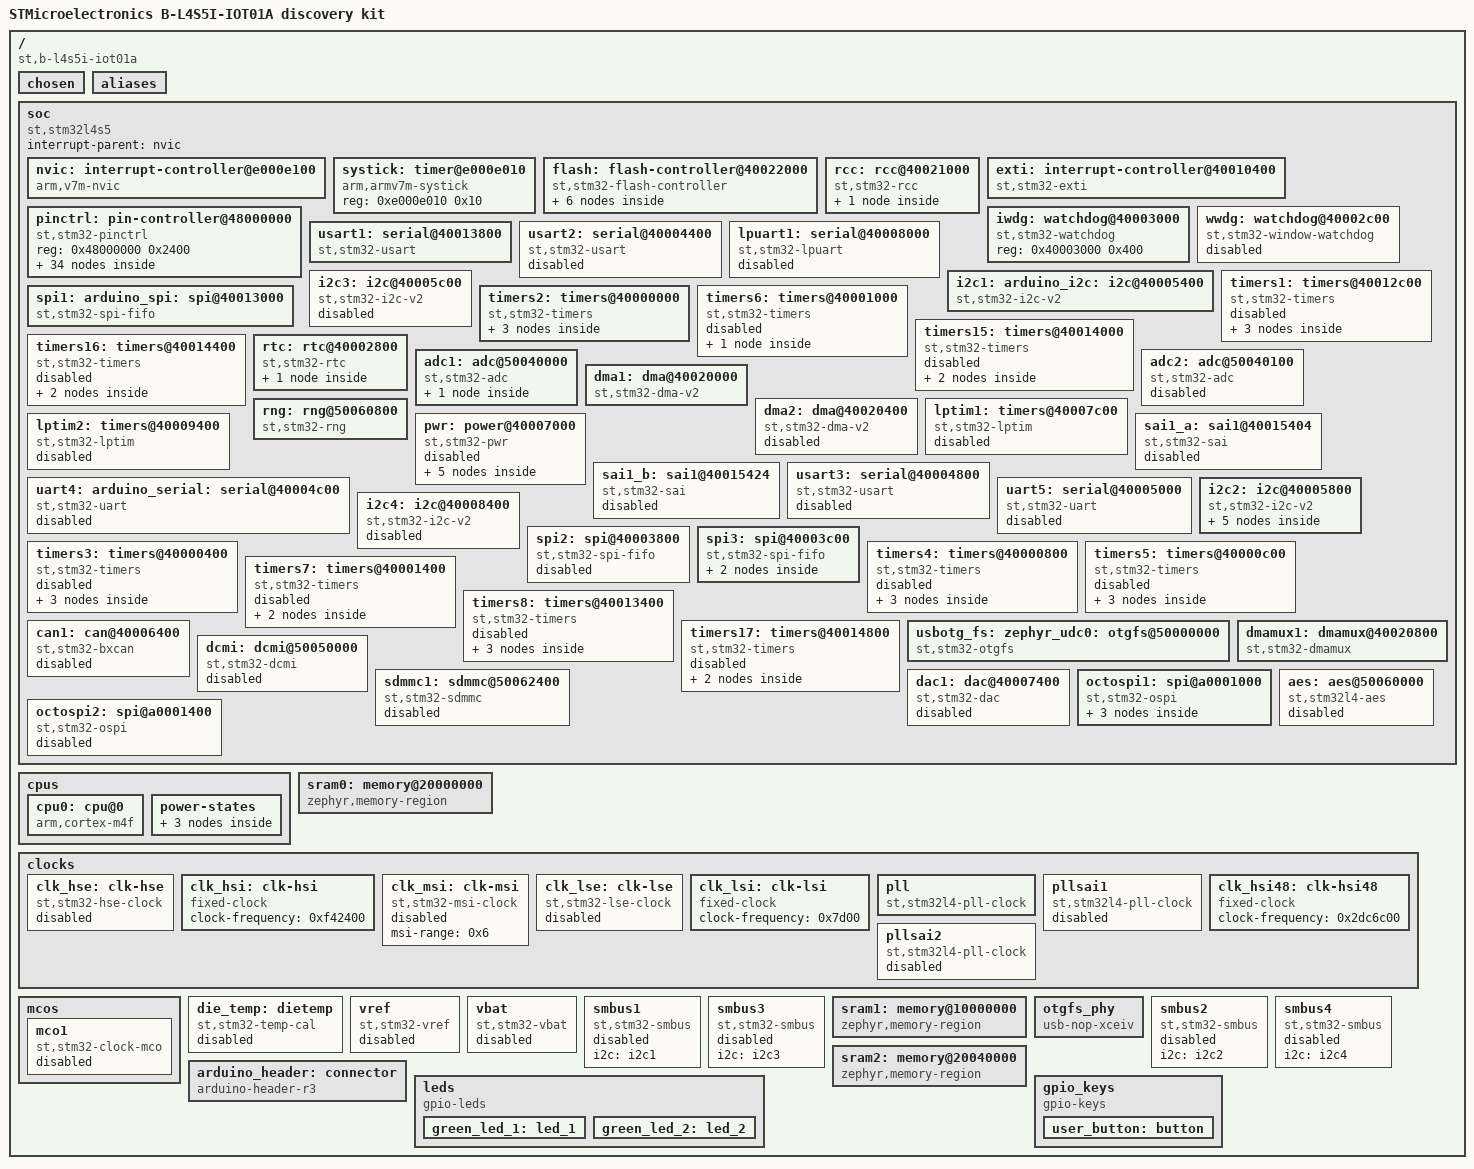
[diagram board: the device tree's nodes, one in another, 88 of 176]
/dts-v1/;

/* node '/' defined in zephyr\dts\common\skeleton.dtsi:9 */
/ {
	#address-cells = < 0x1 >;                                  /* in zephyr\dts\common\skeleton.dtsi:10 */
	#size-cells = < 0x1 >;                                     /* in zephyr\dts\common\skeleton.dtsi:11 */
	model = "STMicroelectronics B-L4S5I-IOT01A discovery kit"; /* in zephyr\boards\st\b_l4s5i_iot01a\b_l4s5i_iot01a.dts:14 */
	compatible = "st,b-l4s5i-iot01a";                          /* in zephyr\boards\st\b_l4s5i_iot01a\b_l4s5i_iot01a.dts:15 */

	/* node '/chosen' defined in zephyr\dts\common\skeleton.dtsi:13 */
	chosen {
		zephyr,entropy = &rng;                    /* in zephyr\dts\arm\st\l4\stm32l4.dtsi:25 */
		zephyr,console = &usart1;                 /* in zephyr\boards\st\b_l4s5i_iot01a\b_l4s5i_iot01a.dts:18 */
		zephyr,shell-uart = &usart1;              /* in zephyr\boards\st\b_l4s5i_iot01a\b_l4s5i_iot01a.dts:19 */
		zephyr,sram = &sram0;                     /* in zephyr\boards\st\b_l4s5i_iot01a\b_l4s5i_iot01a.dts:20 */
		zephyr,flash = &flash0;                   /* in zephyr\boards\st\b_l4s5i_iot01a\b_l4s5i_iot01a.dts:21 */
		zephyr,code-partition = &slot0_partition; /* in zephyr\boards\st\b_l4s5i_iot01a\b_l4s5i_iot01a.dts:22 */
		zephyr,flash-controller = &mx25r6435f;    /* in zephyr\boards\st\b_l4s5i_iot01a\b_l4s5i_iot01a.dts:23 */
		zephyr,bt-c2h-uart = &usart1;             /* in zephyr\boards\st\b_l4s5i_iot01a\b_l4s5i_iot01a.dts:24 */
		zephyr,bt-hci = &hci_spi;                 /* in zephyr\boards\st\b_l4s5i_iot01a\b_l4s5i_iot01a.dts:25 */
	};

	/* node '/aliases' defined in zephyr\dts\common\skeleton.dtsi:15 */
	aliases {
		led0 = &green_led_1; /* in zephyr\boards\st\b_l4s5i_iot01a\b_l4s5i_iot01a.dts:53 */
		sw0 = &user_button;  /* in zephyr\boards\st\b_l4s5i_iot01a\b_l4s5i_iot01a.dts:54 */
		watchdog0 = &iwdg;   /* in zephyr\boards\st\b_l4s5i_iot01a\b_l4s5i_iot01a.dts:55 */
		accel0 = &lsm6dsl;   /* in zephyr\boards\st\b_l4s5i_iot01a\b_l4s5i_iot01a.dts:56 */
	};

	/* node '/soc' defined in zephyr\dts\arm\armv7-m.dtsi:6 */
	soc {
		#address-cells = < 0x1 >;     /* in zephyr\dts\arm\armv7-m.dtsi:7 */
		#size-cells = < 0x1 >;        /* in zephyr\dts\arm\armv7-m.dtsi:8 */
		interrupt-parent = < &nvic >; /* in zephyr\dts\arm\armv7-m.dtsi:10 */
		ranges;                       /* in zephyr\dts\arm\armv7-m.dtsi:11 */
		compatible = "st,stm32l4s5",
		             "st,stm32l4",
		             "simple-bus";    /* in zephyr\dts\arm\st\l4\stm32l4s5.dtsi:11 */

		/* node '/soc/interrupt-controller@e000e100' defined in zephyr\dts\arm\armv7-m.dtsi:13 */
		nvic: interrupt-controller@e000e100 {
			#address-cells = < 0x1 >;            /* in zephyr\dts\arm\armv7-m.dtsi:14 */
			compatible = "arm,v7m-nvic";         /* in zephyr\dts\arm\armv7-m.dtsi:15 */
			reg = < 0xe000e100 0xc00 >;          /* in zephyr\dts\arm\armv7-m.dtsi:16 */
			interrupt-controller;                /* in zephyr\dts\arm\armv7-m.dtsi:17 */
			#interrupt-cells = < 0x2 >;          /* in zephyr\dts\arm\armv7-m.dtsi:18 */
			arm,num-irq-priority-bits = < 0x4 >; /* in zephyr\dts\arm\st\l4\stm32l4.dtsi:597 */
			phandle = < 0x1 >;                   /* in zephyr\dts\arm\armv7-m.dtsi:10 */
		};

		/* node '/soc/timer@e000e010' defined in zephyr\dts\arm\armv7-m.dtsi:21 */
		systick: timer@e000e010 {
			compatible = "arm,armv7m-systick"; /* in zephyr\dts\arm\armv7-m.dtsi:22 */
			reg = < 0xe000e010 0x10 >;         /* in zephyr\dts\arm\armv7-m.dtsi:23 */
		};

		/* node '/soc/flash-controller@40022000' defined in zephyr\dts\arm\st\l4\stm32l4.dtsi:126 */
		flash: flash-controller@40022000 {
			compatible = "st,stm32-flash-controller",
			             "st,stm32l4-flash-controller"; /* in zephyr\dts\arm\st\l4\stm32l4.dtsi:127 */
			reg = < 0x40022000 0x400 >;                 /* in zephyr\dts\arm\st\l4\stm32l4.dtsi:128 */
			interrupts = < 0x4 0x0 >;                   /* in zephyr\dts\arm\st\l4\stm32l4.dtsi:129 */
			clocks = < &rcc 0x48 0x100 >;               /* in zephyr\dts\arm\st\l4\stm32l4.dtsi:130 */
			#address-cells = < 0x1 >;                   /* in zephyr\dts\arm\st\l4\stm32l4.dtsi:132 */
			#size-cells = < 0x1 >;                      /* in zephyr\dts\arm\st\l4\stm32l4.dtsi:133 */

			/* node '/soc/flash-controller@40022000/flash@8000000' defined in zephyr\dts\arm\st\l4\stm32l4.dtsi:135 */
			flash0: flash@8000000 {
				compatible = "st,stm32-nv-flash",
				             "soc-nv-flash";      /* in zephyr\dts\arm\st\l4\stm32l4.dtsi:136 */
				write-block-size = < 0x8 >;       /* in zephyr\dts\arm\st\l4\stm32l4.dtsi:138 */
				max-erase-time = < 0x19 >;        /* in zephyr\dts\arm\st\l4\stm32l4.dtsi:141 */
				erase-block-size = < 0x1000 >;    /* in zephyr\dts\arm\st\l4\stm32l4p5.dtsi:53 */
				reg = < 0x8000000 0x200000 >;     /* in zephyr\dts\arm\st\l4\stm32l4s5Xi.dtsi:13 */

				/* node '/soc/flash-controller@40022000/flash@8000000/partitions' defined in zephyr\boards\st\b_l4s5i_iot01a\b_l4s5i_iot01a.dts:179 */
				partitions {
					compatible = "fixed-partitions"; /* in zephyr\boards\st\b_l4s5i_iot01a\b_l4s5i_iot01a.dts:180 */
					#address-cells = < 0x1 >;        /* in zephyr\boards\st\b_l4s5i_iot01a\b_l4s5i_iot01a.dts:181 */
					#size-cells = < 0x1 >;           /* in zephyr\boards\st\b_l4s5i_iot01a\b_l4s5i_iot01a.dts:182 */

					/* node '/soc/flash-controller@40022000/flash@8000000/partitions/partition@0' defined in zephyr\boards\st\b_l4s5i_iot01a\b_l4s5i_iot01a.dts:184 */
					boot_partition: partition@0 {
						label = "mcuboot";     /* in zephyr\boards\st\b_l4s5i_iot01a\b_l4s5i_iot01a.dts:185 */
						reg = < 0x0 0x10000 >; /* in zephyr\boards\st\b_l4s5i_iot01a\b_l4s5i_iot01a.dts:186 */
						read-only;             /* in zephyr\boards\st\b_l4s5i_iot01a\b_l4s5i_iot01a.dts:187 */
					};

					/* node '/soc/flash-controller@40022000/flash@8000000/partitions/partition@10000' defined in zephyr\boards\st\b_l4s5i_iot01a\b_l4s5i_iot01a.dts:190 */
					slot0_partition: partition@10000 {
						label = "image-0";         /* in zephyr\boards\st\b_l4s5i_iot01a\b_l4s5i_iot01a.dts:191 */
						reg = < 0x10000 0xf4000 >; /* in zephyr\boards\st\b_l4s5i_iot01a\b_l4s5i_iot01a.dts:192 */
					};

					/* node '/soc/flash-controller@40022000/flash@8000000/partitions/partition@104000' defined in zephyr\boards\st\b_l4s5i_iot01a\b_l4s5i_iot01a.dts:195 */
					slot1_partition: partition@104000 {
						label = "image-1";          /* in zephyr\boards\st\b_l4s5i_iot01a\b_l4s5i_iot01a.dts:196 */
						reg = < 0x104000 0xf4000 >; /* in zephyr\boards\st\b_l4s5i_iot01a\b_l4s5i_iot01a.dts:197 */
					};

					/* node '/soc/flash-controller@40022000/flash@8000000/partitions/partition@1f8000' defined in zephyr\boards\st\b_l4s5i_iot01a\b_l4s5i_iot01a.dts:200 */
					storage_partition: partition@1f8000 {
						label = "storage";         /* in zephyr\boards\st\b_l4s5i_iot01a\b_l4s5i_iot01a.dts:201 */
						reg = < 0x1f8000 0x8000 >; /* in zephyr\boards\st\b_l4s5i_iot01a\b_l4s5i_iot01a.dts:202 */
					};
				};
			};
		};

		/* node '/soc/rcc@40021000' defined in zephyr\dts\arm\st\l4\stm32l4.dtsi:145 */
		rcc: rcc@40021000 {
			compatible = "st,stm32-rcc";     /* in zephyr\dts\arm\st\l4\stm32l4.dtsi:146 */
			#clock-cells = < 0x2 >;          /* in zephyr\dts\arm\st\l4\stm32l4.dtsi:147 */
			reg = < 0x40021000 0x400 >;      /* in zephyr\dts\arm\st\l4\stm32l4.dtsi:148 */
			undershoot-prevention;           /* in zephyr\dts\arm\st\l4\stm32l4p5.dtsi:58 */
			clocks = < &pll >;               /* in zephyr\boards\st\b_l4s5i_iot01a\b_l4s5i_iot01a.dts:82 */
			clock-frequency = < 0x4c4b400 >; /* in zephyr\boards\st\b_l4s5i_iot01a\b_l4s5i_iot01a.dts:83 */
			ahb-prescaler = < 0x1 >;         /* in zephyr\boards\st\b_l4s5i_iot01a\b_l4s5i_iot01a.dts:84 */
			apb1-prescaler = < 0x1 >;        /* in zephyr\boards\st\b_l4s5i_iot01a\b_l4s5i_iot01a.dts:85 */
			apb2-prescaler = < 0x1 >;        /* in zephyr\boards\st\b_l4s5i_iot01a\b_l4s5i_iot01a.dts:86 */
			phandle = < 0x2 >;               /* in zephyr\dts\arm\st\l4\stm32l4.dtsi:130 */

			/* node '/soc/rcc@40021000/reset-controller' defined in zephyr\dts\arm\st\l4\stm32l4.dtsi:150 */
			rctl: reset-controller {
				compatible = "st,stm32-rcc-rctl"; /* in zephyr\dts\arm\st\l4\stm32l4.dtsi:151 */
				#reset-cells = < 0x1 >;           /* in zephyr\dts\arm\st\l4\stm32l4.dtsi:152 */
				phandle = < 0x4 >;                /* in zephyr\dts\arm\st\l4\stm32l4.dtsi:229 */
			};
		};

		/* node '/soc/interrupt-controller@40010400' defined in zephyr\dts\arm\st\l4\stm32l4.dtsi:156 */
		exti: interrupt-controller@40010400 {
			compatible = "st,stm32-exti";  /* in zephyr\dts\arm\st\l4\stm32l4.dtsi:157 */
			interrupt-controller;          /* in zephyr\dts\arm\st\l4\stm32l4.dtsi:158 */
			#interrupt-cells = < 0x1 >;    /* in zephyr\dts\arm\st\l4\stm32l4.dtsi:159 */
			#address-cells = < 0x0 >;      /* in zephyr\dts\arm\st\l4\stm32l4.dtsi:160 */
			reg = < 0x40010400 0x400 >;    /* in zephyr\dts\arm\st\l4\stm32l4.dtsi:161 */
			clocks = < &rcc 0x60 0x1 >;    /* in zephyr\dts\arm\st\l4\stm32l4.dtsi:162 */
			num-lines = < 0x40 >;          /* in zephyr\dts\arm\st\l4\stm32l4.dtsi:163 */
			interrupts = < 0x6 0x0 >,
			             < 0x7 0x0 >,
			             < 0x8 0x0 >,
			             < 0x9 0x0 >,
			             < 0xa 0x0 >,
			             < 0x17 0x0 >,
			             < 0x28 0x0 >;     /* in zephyr\dts\arm\st\l4\stm32l4.dtsi:164 */
			interrupt-names = "line0",
			                  "line1",
			                  "line2",
			                  "line3",
			                  "line4",
			                  "line5-9",
			                  "line10-15"; /* in zephyr\dts\arm\st\l4\stm32l4.dtsi:166 */
			line-ranges = < 0x0 0x1 >,
			              < 0x1 0x1 >,
			              < 0x2 0x1 >,
			              < 0x3 0x1 >,
			              < 0x4 0x1 >,
			              < 0x5 0x5 >,
			              < 0xa 0x6 >;     /* in zephyr\dts\arm\st\l4\stm32l4.dtsi:168 */
		};

		/* node '/soc/pin-controller@48000000' defined in zephyr\dts\arm\st\l4\stm32l4.dtsi:172 */
		pinctrl: pin-controller@48000000 {
			compatible = "st,stm32-pinctrl"; /* in zephyr\dts\arm\st\l4\stm32l4.dtsi:173 */
			#address-cells = < 0x1 >;        /* in zephyr\dts\arm\st\l4\stm32l4.dtsi:174 */
			#size-cells = < 0x1 >;           /* in zephyr\dts\arm\st\l4\stm32l4.dtsi:175 */
			reg = < 0x48000000 0x2400 >;     /* in zephyr\dts\arm\st\l4\stm32l4p5.dtsi:67 */

			/* node '/soc/pin-controller@48000000/gpio@48000000' defined in zephyr\dts\arm\st\l4\stm32l4.dtsi:178 */
			gpioa: gpio@48000000 {
				compatible = "st,stm32-gpio"; /* in zephyr\dts\arm\st\l4\stm32l4.dtsi:179 */
				gpio-controller;              /* in zephyr\dts\arm\st\l4\stm32l4.dtsi:180 */
				#gpio-cells = < 0x2 >;        /* in zephyr\dts\arm\st\l4\stm32l4.dtsi:181 */
				reg = < 0x48000000 0x400 >;   /* in zephyr\dts\arm\st\l4\stm32l4.dtsi:182 */
				clocks = < &rcc 0x4c 0x1 >;   /* in zephyr\dts\arm\st\l4\stm32l4.dtsi:183 */
				phandle = < 0xc >;            /* in zephyr\boards\st\b_l4s5i_iot01a\b_l4s5i_iot01a.dts:146 */
			};

			/* node '/soc/pin-controller@48000000/gpio@48000400' defined in zephyr\dts\arm\st\l4\stm32l4.dtsi:186 */
			gpiob: gpio@48000400 {
				compatible = "st,stm32-gpio"; /* in zephyr\dts\arm\st\l4\stm32l4.dtsi:187 */
				gpio-controller;              /* in zephyr\dts\arm\st\l4\stm32l4.dtsi:188 */
				#gpio-cells = < 0x2 >;        /* in zephyr\dts\arm\st\l4\stm32l4.dtsi:189 */
				reg = < 0x48000400 0x400 >;   /* in zephyr\dts\arm\st\l4\stm32l4.dtsi:190 */
				clocks = < &rcc 0x4c 0x2 >;   /* in zephyr\dts\arm\st\l4\stm32l4.dtsi:191 */
				phandle = < 0x1a >;           /* in zephyr\boards\st\b_l4s5i_iot01a\b_l4s5i_iot01a.dts:172 */
			};

			/* node '/soc/pin-controller@48000000/gpio@48000800' defined in zephyr\dts\arm\st\l4\stm32l4.dtsi:194 */
			gpioc: gpio@48000800 {
				compatible = "st,stm32-gpio"; /* in zephyr\dts\arm\st\l4\stm32l4.dtsi:195 */
				gpio-controller;              /* in zephyr\dts\arm\st\l4\stm32l4.dtsi:196 */
				#gpio-cells = < 0x2 >;        /* in zephyr\dts\arm\st\l4\stm32l4.dtsi:197 */
				reg = < 0x48000800 0x400 >;   /* in zephyr\dts\arm\st\l4\stm32l4.dtsi:198 */
				clocks = < &rcc 0x4c 0x4 >;   /* in zephyr\dts\arm\st\l4\stm32l4.dtsi:199 */
				phandle = < 0x15 >;           /* in zephyr\boards\st\b_l4s5i_iot01a\b_l4s5i_iot01a.dts:139 */
			};

			/* node '/soc/pin-controller@48000000/gpio@48001c00' defined in zephyr\dts\arm\st\l4\stm32l4.dtsi:202 */
			gpioh: gpio@48001c00 {
				compatible = "st,stm32-gpio"; /* in zephyr\dts\arm\st\l4\stm32l4.dtsi:203 */
				gpio-controller;              /* in zephyr\dts\arm\st\l4\stm32l4.dtsi:204 */
				#gpio-cells = < 0x2 >;        /* in zephyr\dts\arm\st\l4\stm32l4.dtsi:205 */
				reg = < 0x48001c00 0x400 >;   /* in zephyr\dts\arm\st\l4\stm32l4.dtsi:206 */
				clocks = < &rcc 0x4c 0x80 >;  /* in zephyr\dts\arm\st\l4\stm32l4.dtsi:207 */
			};

			/* node '/soc/pin-controller@48000000/gpio@48000c00' defined in zephyr\dts\arm\st\l4\stm32l4p5.dtsi:69 */
			gpiod: gpio@48000c00 {
				compatible = "st,stm32-gpio"; /* in zephyr\dts\arm\st\l4\stm32l4p5.dtsi:70 */
				gpio-controller;              /* in zephyr\dts\arm\st\l4\stm32l4p5.dtsi:71 */
				#gpio-cells = < 0x2 >;        /* in zephyr\dts\arm\st\l4\stm32l4p5.dtsi:72 */
				reg = < 0x48000c00 0x400 >;   /* in zephyr\dts\arm\st\l4\stm32l4p5.dtsi:73 */
				clocks = < &rcc 0x4c 0x8 >;   /* in zephyr\dts\arm\st\l4\stm32l4p5.dtsi:74 */
				phandle = < 0x14 >;           /* in zephyr\boards\st\b_l4s5i_iot01a\b_l4s5i_iot01a.dts:133 */
			};

			/* node '/soc/pin-controller@48000000/gpio@48001000' defined in zephyr\dts\arm\st\l4\stm32l4p5.dtsi:77 */
			gpioe: gpio@48001000 {
				compatible = "st,stm32-gpio"; /* in zephyr\dts\arm\st\l4\stm32l4p5.dtsi:78 */
				gpio-controller;              /* in zephyr\dts\arm\st\l4\stm32l4p5.dtsi:79 */
				#gpio-cells = < 0x2 >;        /* in zephyr\dts\arm\st\l4\stm32l4p5.dtsi:80 */
				reg = < 0x48001000 0x400 >;   /* in zephyr\dts\arm\st\l4\stm32l4p5.dtsi:81 */
				clocks = < &rcc 0x4c 0x10 >;  /* in zephyr\dts\arm\st\l4\stm32l4p5.dtsi:82 */
				phandle = < 0x19 >;           /* in zephyr\boards\st\b_l4s5i_iot01a\b_l4s5i_iot01a.dts:155 */
			};

			/* node '/soc/pin-controller@48000000/gpio@48001400' defined in zephyr\dts\arm\st\l4\stm32l4p5.dtsi:85 */
			gpiof: gpio@48001400 {
				compatible = "st,stm32-gpio"; /* in zephyr\dts\arm\st\l4\stm32l4p5.dtsi:86 */
				gpio-controller;              /* in zephyr\dts\arm\st\l4\stm32l4p5.dtsi:87 */
				#gpio-cells = < 0x2 >;        /* in zephyr\dts\arm\st\l4\stm32l4p5.dtsi:88 */
				reg = < 0x48001400 0x400 >;   /* in zephyr\dts\arm\st\l4\stm32l4p5.dtsi:89 */
				clocks = < &rcc 0x4c 0x20 >;  /* in zephyr\dts\arm\st\l4\stm32l4p5.dtsi:90 */
			};

			/* node '/soc/pin-controller@48000000/gpio@48001800' defined in zephyr\dts\arm\st\l4\stm32l4p5.dtsi:93 */
			gpiog: gpio@48001800 {
				compatible = "st,stm32-gpio"; /* in zephyr\dts\arm\st\l4\stm32l4p5.dtsi:94 */
				gpio-controller;              /* in zephyr\dts\arm\st\l4\stm32l4p5.dtsi:95 */
				#gpio-cells = < 0x2 >;        /* in zephyr\dts\arm\st\l4\stm32l4p5.dtsi:96 */
				reg = < 0x48001800 0x400 >;   /* in zephyr\dts\arm\st\l4\stm32l4p5.dtsi:97 */
				clocks = < &rcc 0x4c 0x40 >;  /* in zephyr\dts\arm\st\l4\stm32l4p5.dtsi:98 */
			};

			/* node '/soc/pin-controller@48000000/gpio@48002000' defined in zephyr\dts\arm\st\l4\stm32l4p5.dtsi:101 */
			gpioi: gpio@48002000 {
				compatible = "st,stm32-gpio"; /* in zephyr\dts\arm\st\l4\stm32l4p5.dtsi:102 */
				gpio-controller;              /* in zephyr\dts\arm\st\l4\stm32l4p5.dtsi:103 */
				#gpio-cells = < 0x2 >;        /* in zephyr\dts\arm\st\l4\stm32l4p5.dtsi:104 */
				reg = < 0x48002000 0x400 >;   /* in zephyr\dts\arm\st\l4\stm32l4p5.dtsi:105 */
				clocks = < &rcc 0x4c 0x100 >; /* in zephyr\dts\arm\st\l4\stm32l4p5.dtsi:106 */
			};

			/* node '/soc/pin-controller@48000000/adc1_in1_pc0' defined in modules\hal\stm32\dts\st\l4\stm32l4s5vitx-pinctrl.dtsi:55 */
			adc1_in1_pc0: adc1_in1_pc0 {
				pinmux = < 0x410 >; /* in modules\hal\stm32\dts\st\l4\stm32l4s5vitx-pinctrl.dtsi:56 */
				phandle = < 0xe >;  /* in zephyr\samples\basic\app_test_7\b_l4s5i_iot01a.overlay:3 */
			};

			/* node '/soc/pin-controller@48000000/i2c1_scl_pb8' defined in modules\hal\stm32\dts\st\l4\stm32l4s5vitx-pinctrl.dtsi:1035 */
			i2c1_scl_pb8: i2c1_scl_pb8 {
				pinmux = < 0x304 >; /* in modules\hal\stm32\dts\st\l4\stm32l4s5vitx-pinctrl.dtsi:1036 */
				bias-pull-up;       /* in modules\hal\stm32\dts\st\l4\stm32l4s5vitx-pinctrl.dtsi:1037 */
				drive-open-drain;   /* in modules\hal\stm32\dts\st\l4\stm32l4s5vitx-pinctrl.dtsi:1038 */
				phandle = < 0x7 >;  /* in zephyr\boards\st\b_l4s5i_iot01a\b_l4s5i_iot01a.dts:103 */
			};

			/* node '/soc/pin-controller@48000000/i2c2_scl_pb10' defined in modules\hal\stm32\dts\st\l4\stm32l4s5vitx-pinctrl.dtsi:1041 */
			i2c2_scl_pb10: i2c2_scl_pb10 {
				pinmux = < 0x344 >; /* in modules\hal\stm32\dts\st\l4\stm32l4s5vitx-pinctrl.dtsi:1042 */
				bias-pull-up;       /* in modules\hal\stm32\dts\st\l4\stm32l4s5vitx-pinctrl.dtsi:1043 */
				drive-open-drain;   /* in modules\hal\stm32\dts\st\l4\stm32l4s5vitx-pinctrl.dtsi:1044 */
				phandle = < 0x12 >; /* in zephyr\boards\st\b_l4s5i_iot01a\b_l4s5i_iot01a.dts:110 */
			};

			/* node '/soc/pin-controller@48000000/i2c1_sda_pb9' defined in modules\hal\stm32\dts\st\l4\stm32l4s5vitx-pinctrl.dtsi:1091 */
			i2c1_sda_pb9: i2c1_sda_pb9 {
				pinmux = < 0x324 >; /* in modules\hal\stm32\dts\st\l4\stm32l4s5vitx-pinctrl.dtsi:1092 */
				bias-pull-up;       /* in modules\hal\stm32\dts\st\l4\stm32l4s5vitx-pinctrl.dtsi:1093 */
				drive-open-drain;   /* in modules\hal\stm32\dts\st\l4\stm32l4s5vitx-pinctrl.dtsi:1094 */
				phandle = < 0x8 >;  /* in zephyr\boards\st\b_l4s5i_iot01a\b_l4s5i_iot01a.dts:103 */
			};

			/* node '/soc/pin-controller@48000000/i2c2_sda_pb11' defined in modules\hal\stm32\dts\st\l4\stm32l4s5vitx-pinctrl.dtsi:1097 */
			i2c2_sda_pb11: i2c2_sda_pb11 {
				pinmux = < 0x364 >; /* in modules\hal\stm32\dts\st\l4\stm32l4s5vitx-pinctrl.dtsi:1098 */
				bias-pull-up;       /* in modules\hal\stm32\dts\st\l4\stm32l4s5vitx-pinctrl.dtsi:1099 */
				drive-open-drain;   /* in modules\hal\stm32\dts\st\l4\stm32l4s5vitx-pinctrl.dtsi:1100 */
				phandle = < 0x13 >; /* in zephyr\boards\st\b_l4s5i_iot01a\b_l4s5i_iot01a.dts:110 */
			};

			/* node '/soc/pin-controller@48000000/octospim_p1_clk_pe10' defined in modules\hal\stm32\dts\st\l4\stm32l4s5vitx-pinctrl.dtsi:1390 */
			octospim_p1_clk_pe10: octospim_p1_clk_pe10 {
				pinmux = < 0x94a >;            /* in modules\hal\stm32\dts\st\l4\stm32l4s5vitx-pinctrl.dtsi:1391 */
				slew-rate = "very-high-speed"; /* in modules\hal\stm32\dts\st\l4\stm32l4s5vitx-pinctrl.dtsi:1392 */
				phandle = < 0x20 >;            /* in zephyr\boards\st\b_l4s5i_iot01a\b_l4s5i_iot01a.dts:239 */
			};

			/* node '/soc/pin-controller@48000000/octospim_p1_ncs_pe11' defined in modules\hal\stm32\dts\st\l4\stm32l4s5vitx-pinctrl.dtsi:1395 */
			octospim_p1_ncs_pe11: octospim_p1_ncs_pe11 {
				pinmux = < 0x96a >;            /* in modules\hal\stm32\dts\st\l4\stm32l4s5vitx-pinctrl.dtsi:1396 */
				slew-rate = "very-high-speed"; /* in modules\hal\stm32\dts\st\l4\stm32l4s5vitx-pinctrl.dtsi:1397 */
				phandle = < 0x21 >;            /* in zephyr\boards\st\b_l4s5i_iot01a\b_l4s5i_iot01a.dts:239 */
			};

			/* node '/soc/pin-controller@48000000/octospim_p1_io0_pe12' defined in modules\hal\stm32\dts\st\l4\stm32l4s5vitx-pinctrl.dtsi:1400 */
			octospim_p1_io0_pe12: octospim_p1_io0_pe12 {
				pinmux = < 0x98a >;            /* in modules\hal\stm32\dts\st\l4\stm32l4s5vitx-pinctrl.dtsi:1401 */
				slew-rate = "very-high-speed"; /* in modules\hal\stm32\dts\st\l4\stm32l4s5vitx-pinctrl.dtsi:1402 */
				phandle = < 0x22 >;            /* in zephyr\boards\st\b_l4s5i_iot01a\b_l4s5i_iot01a.dts:239 */
			};

			/* node '/soc/pin-controller@48000000/octospim_p1_io1_pe13' defined in modules\hal\stm32\dts\st\l4\stm32l4s5vitx-pinctrl.dtsi:1405 */
			octospim_p1_io1_pe13: octospim_p1_io1_pe13 {
				pinmux = < 0x9aa >;            /* in modules\hal\stm32\dts\st\l4\stm32l4s5vitx-pinctrl.dtsi:1406 */
				slew-rate = "very-high-speed"; /* in modules\hal\stm32\dts\st\l4\stm32l4s5vitx-pinctrl.dtsi:1407 */
				phandle = < 0x23 >;            /* in zephyr\boards\st\b_l4s5i_iot01a\b_l4s5i_iot01a.dts:239 */
			};

			/* node '/soc/pin-controller@48000000/octospim_p1_io2_pe14' defined in modules\hal\stm32\dts\st\l4\stm32l4s5vitx-pinctrl.dtsi:1410 */
			octospim_p1_io2_pe14: octospim_p1_io2_pe14 {
				pinmux = < 0x9ca >;            /* in modules\hal\stm32\dts\st\l4\stm32l4s5vitx-pinctrl.dtsi:1411 */
				slew-rate = "very-high-speed"; /* in modules\hal\stm32\dts\st\l4\stm32l4s5vitx-pinctrl.dtsi:1412 */
				phandle = < 0x24 >;            /* in zephyr\boards\st\b_l4s5i_iot01a\b_l4s5i_iot01a.dts:239 */
			};

			/* node '/soc/pin-controller@48000000/octospim_p1_io3_pe15' defined in modules\hal\stm32\dts\st\l4\stm32l4s5vitx-pinctrl.dtsi:1415 */
			octospim_p1_io3_pe15: octospim_p1_io3_pe15 {
				pinmux = < 0x9ea >;            /* in modules\hal\stm32\dts\st\l4\stm32l4s5vitx-pinctrl.dtsi:1416 */
				slew-rate = "very-high-speed"; /* in modules\hal\stm32\dts\st\l4\stm32l4s5vitx-pinctrl.dtsi:1417 */
				phandle = < 0x25 >;            /* in zephyr\boards\st\b_l4s5i_iot01a\b_l4s5i_iot01a.dts:239 */
			};

			/* node '/soc/pin-controller@48000000/spi1_miso_pa6' defined in modules\hal\stm32\dts\st\l4\stm32l4s5vitx-pinctrl.dtsi:1771 */
			spi1_miso_pa6: spi1_miso_pa6 {
				pinmux = < 0xc5 >;             /* in modules\hal\stm32\dts\st\l4\stm32l4s5vitx-pinctrl.dtsi:1772 */
				bias-pull-down;                /* in modules\hal\stm32\dts\st\l4\stm32l4s5vitx-pinctrl.dtsi:1773 */
				slew-rate = "very-high-speed"; /* in modules\hal\stm32\dts\st\l4\stm32l4s5vitx-pinctrl.dtsi:1774 */
				phandle = < 0xa >;             /* in zephyr\boards\st\b_l4s5i_iot01a\b_l4s5i_iot01a.dts:144 */
			};

			/* node '/soc/pin-controller@48000000/spi3_miso_pc11' defined in modules\hal\stm32\dts\st\l4\stm32l4s5vitx-pinctrl.dtsi:1819 */
			spi3_miso_pc11: spi3_miso_pc11 {
				pinmux = < 0x566 >;            /* in modules\hal\stm32\dts\st\l4\stm32l4s5vitx-pinctrl.dtsi:1820 */
				bias-pull-down;                /* in modules\hal\stm32\dts\st\l4\stm32l4s5vitx-pinctrl.dtsi:1821 */
				slew-rate = "very-high-speed"; /* in modules\hal\stm32\dts\st\l4\stm32l4s5vitx-pinctrl.dtsi:1822 */
				phandle = < 0x17 >;            /* in zephyr\boards\st\b_l4s5i_iot01a\b_l4s5i_iot01a.dts:151 */
			};

			/* node '/soc/pin-controller@48000000/spi1_mosi_pa7' defined in modules\hal\stm32\dts\st\l4\stm32l4s5vitx-pinctrl.dtsi:1827 */
			spi1_mosi_pa7: spi1_mosi_pa7 {
				pinmux = < 0xe5 >;             /* in modules\hal\stm32\dts\st\l4\stm32l4s5vitx-pinctrl.dtsi:1828 */
				bias-pull-down;                /* in modules\hal\stm32\dts\st\l4\stm32l4s5vitx-pinctrl.dtsi:1829 */
				slew-rate = "very-high-speed"; /* in modules\hal\stm32\dts\st\l4\stm32l4s5vitx-pinctrl.dtsi:1830 */
				phandle = < 0xb >;             /* in zephyr\boards\st\b_l4s5i_iot01a\b_l4s5i_iot01a.dts:144 */
			};

			/* node '/soc/pin-controller@48000000/spi3_mosi_pc12' defined in modules\hal\stm32\dts\st\l4\stm32l4s5vitx-pinctrl.dtsi:1881 */
			spi3_mosi_pc12: spi3_mosi_pc12 {
				pinmux = < 0x586 >;            /* in modules\hal\stm32\dts\st\l4\stm32l4s5vitx-pinctrl.dtsi:1882 */
				bias-pull-down;                /* in modules\hal\stm32\dts\st\l4\stm32l4s5vitx-pinctrl.dtsi:1883 */
				slew-rate = "very-high-speed"; /* in modules\hal\stm32\dts\st\l4\stm32l4s5vitx-pinctrl.dtsi:1884 */
				phandle = < 0x18 >;            /* in zephyr\boards\st\b_l4s5i_iot01a\b_l4s5i_iot01a.dts:151 */
			};

			/* node '/soc/pin-controller@48000000/spi1_sck_pa5' defined in modules\hal\stm32\dts\st\l4\stm32l4s5vitx-pinctrl.dtsi:1957 */
			spi1_sck_pa5: spi1_sck_pa5 {
				pinmux = < 0xa5 >;             /* in modules\hal\stm32\dts\st\l4\stm32l4s5vitx-pinctrl.dtsi:1958 */
				bias-pull-down;                /* in modules\hal\stm32\dts\st\l4\stm32l4s5vitx-pinctrl.dtsi:1959 */
				slew-rate = "very-high-speed"; /* in modules\hal\stm32\dts\st\l4\stm32l4s5vitx-pinctrl.dtsi:1960 */
				phandle = < 0x9 >;             /* in zephyr\boards\st\b_l4s5i_iot01a\b_l4s5i_iot01a.dts:144 */
			};

			/* node '/soc/pin-controller@48000000/spi3_sck_pc10' defined in modules\hal\stm32\dts\st\l4\stm32l4s5vitx-pinctrl.dtsi:2011 */
			spi3_sck_pc10: spi3_sck_pc10 {
				pinmux = < 0x546 >;            /* in modules\hal\stm32\dts\st\l4\stm32l4s5vitx-pinctrl.dtsi:2012 */
				bias-pull-down;                /* in modules\hal\stm32\dts\st\l4\stm32l4s5vitx-pinctrl.dtsi:2013 */
				slew-rate = "very-high-speed"; /* in modules\hal\stm32\dts\st\l4\stm32l4s5vitx-pinctrl.dtsi:2014 */
				phandle = < 0x16 >;            /* in zephyr\boards\st\b_l4s5i_iot01a\b_l4s5i_iot01a.dts:151 */
			};

			/* node '/soc/pin-controller@48000000/tim2_ch1_pa15' defined in modules\hal\stm32\dts\st\l4\stm32l4s5vitx-pinctrl.dtsi:2165 */
			tim2_ch1_pa15: tim2_ch1_pa15 {
				pinmux = < 0x1e1 >; /* in modules\hal\stm32\dts\st\l4\stm32l4s5vitx-pinctrl.dtsi:2166 */
				phandle = < 0xd >;  /* in zephyr\boards\st\b_l4s5i_iot01a\b_l4s5i_iot01a.dts:212 */
			};

			/* node '/soc/pin-controller@48000000/usart1_rx_pb7' defined in modules\hal\stm32\dts\st\l4\stm32l4s5vitx-pinctrl.dtsi:2704 */
			usart1_rx_pb7: usart1_rx_pb7 {
				pinmux = < 0x2e7 >; /* in modules\hal\stm32\dts\st\l4\stm32l4s5vitx-pinctrl.dtsi:2705 */
				phandle = < 0x6 >;  /* in zephyr\boards\st\b_l4s5i_iot01a\b_l4s5i_iot01a.dts:90 */
			};

			/* node '/soc/pin-controller@48000000/uart4_rx_pa1' defined in modules\hal\stm32\dts\st\l4\stm32l4s5vitx-pinctrl.dtsi:2744 */
			uart4_rx_pa1: uart4_rx_pa1 {
				pinmux = < 0x28 >;  /* in modules\hal\stm32\dts\st\l4\stm32l4s5vitx-pinctrl.dtsi:2745 */
				phandle = < 0x11 >; /* in zephyr\boards\st\b_l4s5i_iot01a\b_l4s5i_iot01a.dts:97 */
			};

			/* node '/soc/pin-controller@48000000/usart1_tx_pb6' defined in modules\hal\stm32\dts\st\l4\stm32l4s5vitx-pinctrl.dtsi:2768 */
			usart1_tx_pb6: usart1_tx_pb6 {
				pinmux = < 0x2c7 >; /* in modules\hal\stm32\dts\st\l4\stm32l4s5vitx-pinctrl.dtsi:2769 */
				bias-pull-up;       /* in modules\hal\stm32\dts\st\l4\stm32l4s5vitx-pinctrl.dtsi:2770 */
				phandle = < 0x5 >;  /* in zephyr\boards\st\b_l4s5i_iot01a\b_l4s5i_iot01a.dts:90 */
			};

			/* node '/soc/pin-controller@48000000/uart4_tx_pa0' defined in modules\hal\stm32\dts\st\l4\stm32l4s5vitx-pinctrl.dtsi:2813 */
			uart4_tx_pa0: uart4_tx_pa0 {
				pinmux = < 0x8 >;   /* in modules\hal\stm32\dts\st\l4\stm32l4s5vitx-pinctrl.dtsi:2814 */
				bias-pull-up;       /* in modules\hal\stm32\dts\st\l4\stm32l4s5vitx-pinctrl.dtsi:2815 */
				phandle = < 0x10 >; /* in zephyr\boards\st\b_l4s5i_iot01a\b_l4s5i_iot01a.dts:97 */
			};

			/* node '/soc/pin-controller@48000000/usb_otg_fs_id_pa10' defined in modules\hal\stm32\dts\st\l4\stm32l4s5vitx-pinctrl.dtsi:2838 */
			usb_otg_fs_id_pa10: usb_otg_fs_id_pa10 {
				pinmux = < 0x14a >; /* in modules\hal\stm32\dts\st\l4\stm32l4s5vitx-pinctrl.dtsi:2839 */
				phandle = < 0x1e >; /* in zephyr\boards\st\b_l4s5i_iot01a\b_l4s5i_iot01a.dts:224 */
			};

			/* node '/soc/pin-controller@48000000/usb_otg_fs_dm_pa11' defined in modules\hal\stm32\dts\st\l4\stm32l4s5vitx-pinctrl.dtsi:2842 */
			usb_otg_fs_dm_pa11: usb_otg_fs_dm_pa11 {
				pinmux = < 0x16a >; /* in modules\hal\stm32\dts\st\l4\stm32l4s5vitx-pinctrl.dtsi:2843 */
				phandle = < 0x1c >; /* in zephyr\boards\st\b_l4s5i_iot01a\b_l4s5i_iot01a.dts:224 */
			};

			/* node '/soc/pin-controller@48000000/usb_otg_fs_dp_pa12' defined in modules\hal\stm32\dts\st\l4\stm32l4s5vitx-pinctrl.dtsi:2846 */
			usb_otg_fs_dp_pa12: usb_otg_fs_dp_pa12 {
				pinmux = < 0x18a >; /* in modules\hal\stm32\dts\st\l4\stm32l4s5vitx-pinctrl.dtsi:2847 */
				phandle = < 0x1d >; /* in zephyr\boards\st\b_l4s5i_iot01a\b_l4s5i_iot01a.dts:224 */
			};
		};

		/* node '/soc/watchdog@40003000' defined in zephyr\dts\arm\st\l4\stm32l4.dtsi:211 */
		iwdg: watchdog@40003000 {
			compatible = "st,stm32-watchdog"; /* in zephyr\dts\arm\st\l4\stm32l4.dtsi:212 */
			reg = < 0x40003000 0x400 >;       /* in zephyr\dts\arm\st\l4\stm32l4.dtsi:213 */
			status = "okay";                  /* in zephyr\boards\st\b_l4s5i_iot01a\b_l4s5i_iot01a.dts:231 */
		};

		/* node '/soc/watchdog@40002c00' defined in zephyr\dts\arm\st\l4\stm32l4.dtsi:217 */
		wwdg: watchdog@40002c00 {
			compatible = "st,stm32-window-watchdog"; /* in zephyr\dts\arm\st\l4\stm32l4.dtsi:218 */
			reg = < 0x40002c00 0x400 >;              /* in zephyr\dts\arm\st\l4\stm32l4.dtsi:219 */
			clocks = < &rcc 0x58 0x800 >;            /* in zephyr\dts\arm\st\l4\stm32l4.dtsi:220 */
			interrupts = < 0x0 0x7 >;                /* in zephyr\dts\arm\st\l4\stm32l4.dtsi:221 */
			status = "disabled";                     /* in zephyr\dts\arm\st\l4\stm32l4.dtsi:222 */
		};

		/* node '/soc/serial@40013800' defined in zephyr\dts\arm\st\l4\stm32l4.dtsi:225 */
		usart1: serial@40013800 {
			compatible = "st,stm32-usart",
			             "st,stm32-uart";                  /* in zephyr\dts\arm\st\l4\stm32l4.dtsi:226 */
			reg = < 0x40013800 0x400 >;                    /* in zephyr\dts\arm\st\l4\stm32l4.dtsi:227 */
			clocks = < &rcc 0x60 0x4000 >;                 /* in zephyr\dts\arm\st\l4\stm32l4.dtsi:228 */
			resets = < &rctl 0x80e >;                      /* in zephyr\dts\arm\st\l4\stm32l4.dtsi:229 */
			interrupts = < 0x25 0x0 >;                     /* in zephyr\dts\arm\st\l4\stm32l4.dtsi:230 */
			pinctrl-0 = < &usart1_tx_pb6 &usart1_rx_pb7 >; /* in zephyr\boards\st\b_l4s5i_iot01a\b_l4s5i_iot01a.dts:90 */
			pinctrl-names = "default";                     /* in zephyr\boards\st\b_l4s5i_iot01a\b_l4s5i_iot01a.dts:91 */
			current-speed = < 0x1c200 >;                   /* in zephyr\boards\st\b_l4s5i_iot01a\b_l4s5i_iot01a.dts:92 */
			status = "okay";                               /* in zephyr\boards\st\b_l4s5i_iot01a\b_l4s5i_iot01a.dts:93 */
		};

		/* node '/soc/serial@40004400' defined in zephyr\dts\arm\st\l4\stm32l4.dtsi:234 */
		usart2: serial@40004400 {
			compatible = "st,stm32-usart",
			             "st,stm32-uart";   /* in zephyr\dts\arm\st\l4\stm32l4.dtsi:235 */
			reg = < 0x40004400 0x400 >;     /* in zephyr\dts\arm\st\l4\stm32l4.dtsi:236 */
			clocks = < &rcc 0x58 0x20000 >; /* in zephyr\dts\arm\st\l4\stm32l4.dtsi:237 */
			resets = < &rctl 0x711 >;       /* in zephyr\dts\arm\st\l4\stm32l4.dtsi:238 */
			interrupts = < 0x26 0x0 >;      /* in zephyr\dts\arm\st\l4\stm32l4.dtsi:239 */
			status = "disabled";            /* in zephyr\dts\arm\st\l4\stm32l4.dtsi:240 */
		};

		/* node '/soc/serial@40008000' defined in zephyr\dts\arm\st\l4\stm32l4.dtsi:243 */
		lpuart1: serial@40008000 {
			compatible = "st,stm32-lpuart",
			             "st,stm32-uart";   /* in zephyr\dts\arm\st\l4\stm32l4.dtsi:244 */
			reg = < 0x40008000 0x400 >;     /* in zephyr\dts\arm\st\l4\stm32l4.dtsi:245 */
			clocks = < &rcc 0x5c 0x1 >;     /* in zephyr\dts\arm\st\l4\stm32l4.dtsi:246 */
			resets = < &rctl 0x780 >;       /* in zephyr\dts\arm\st\l4\stm32l4.dtsi:247 */
			interrupts = < 0x46 0x0 >;      /* in zephyr\dts\arm\st\l4\stm32l4.dtsi:248 */
			status = "disabled";            /* in zephyr\dts\arm\st\l4\stm32l4.dtsi:249 */
		};

		/* node '/soc/i2c@40005400' defined in zephyr\dts\arm\st\l4\stm32l4.dtsi:252 */
		i2c1: arduino_i2c: i2c@40005400 {
			compatible = "st,stm32-i2c-v2";              /* in zephyr\dts\arm\st\l4\stm32l4.dtsi:253 */
			#address-cells = < 0x1 >;                    /* in zephyr\dts\arm\st\l4\stm32l4.dtsi:255 */
			#size-cells = < 0x0 >;                       /* in zephyr\dts\arm\st\l4\stm32l4.dtsi:256 */
			reg = < 0x40005400 0x400 >;                  /* in zephyr\dts\arm\st\l4\stm32l4.dtsi:257 */
			clocks = < &rcc 0x58 0x200000 >;             /* in zephyr\dts\arm\st\l4\stm32l4.dtsi:258 */
			interrupts = < 0x1f 0x0 >,
			             < 0x20 0x0 >;                   /* in zephyr\dts\arm\st\l4\stm32l4.dtsi:259 */
			interrupt-names = "event",
			                  "error";                   /* in zephyr\dts\arm\st\l4\stm32l4.dtsi:260 */
			pinctrl-0 = < &i2c1_scl_pb8 &i2c1_sda_pb9 >; /* in zephyr\boards\st\b_l4s5i_iot01a\b_l4s5i_iot01a.dts:103 */
			pinctrl-names = "default";                   /* in zephyr\boards\st\b_l4s5i_iot01a\b_l4s5i_iot01a.dts:104 */
			status = "okay";                             /* in zephyr\boards\st\b_l4s5i_iot01a\b_l4s5i_iot01a.dts:105 */
			clock-frequency = < 0x61a80 >;               /* in zephyr\boards\st\b_l4s5i_iot01a\b_l4s5i_iot01a.dts:106 */
			phandle = < 0x2b >;                          /* in zephyr\dts\arm\st\l4\stm32l4.dtsi:583 */
		};

		/* node '/soc/i2c@40005c00' defined in zephyr\dts\arm\st\l4\stm32l4.dtsi:264 */
		i2c3: i2c@40005c00 {
			compatible = "st,stm32-i2c-v2";  /* in zephyr\dts\arm\st\l4\stm32l4.dtsi:265 */
			clock-frequency = < 0x186a0 >;   /* in zephyr\dts\arm\st\l4\stm32l4.dtsi:266 */
			#address-cells = < 0x1 >;        /* in zephyr\dts\arm\st\l4\stm32l4.dtsi:267 */
			#size-cells = < 0x0 >;           /* in zephyr\dts\arm\st\l4\stm32l4.dtsi:268 */
			reg = < 0x40005c00 0x400 >;      /* in zephyr\dts\arm\st\l4\stm32l4.dtsi:269 */
			clocks = < &rcc 0x58 0x800000 >; /* in zephyr\dts\arm\st\l4\stm32l4.dtsi:270 */
			interrupts = < 0x48 0x0 >,
			             < 0x49 0x0 >;       /* in zephyr\dts\arm\st\l4\stm32l4.dtsi:271 */
			interrupt-names = "event",
			                  "error";       /* in zephyr\dts\arm\st\l4\stm32l4.dtsi:272 */
			status = "disabled";             /* in zephyr\dts\arm\st\l4\stm32l4.dtsi:273 */
			phandle = < 0x2c >;              /* in zephyr\dts\arm\st\l4\stm32l4.dtsi:591 */
		};

		/* node '/soc/spi@40013000' defined in zephyr\dts\arm\st\l4\stm32l4.dtsi:286 */
		spi1: arduino_spi: spi@40013000 {
			compatible = "st,stm32-spi-fifo",
			             "st,stm32-spi";                                 /* in zephyr\dts\arm\st\l4\stm32l4.dtsi:287 */
			#address-cells = < 0x1 >;                                    /* in zephyr\dts\arm\st\l4\stm32l4.dtsi:288 */
			#size-cells = < 0x0 >;                                       /* in zephyr\dts\arm\st\l4\stm32l4.dtsi:289 */
			reg = < 0x40013000 0x400 >;                                  /* in zephyr\dts\arm\st\l4\stm32l4.dtsi:290 */
			interrupts = < 0x23 0x5 >;                                   /* in zephyr\dts\arm\st\l4\stm32l4.dtsi:291 */
			clocks = < &rcc 0x60 0x1000 >;                               /* in zephyr\dts\arm\st\l4\stm32l4.dtsi:292 */
			st,spi-data-width = "full-4-to-16-bit";                      /* in zephyr\dts\arm\st\l4\stm32l4.dtsi:293 */
			pinctrl-0 = < &spi1_sck_pa5 &spi1_miso_pa6 &spi1_mosi_pa7 >; /* in zephyr\boards\st\b_l4s5i_iot01a\b_l4s5i_iot01a.dts:144 */
			pinctrl-names = "default";                                   /* in zephyr\boards\st\b_l4s5i_iot01a\b_l4s5i_iot01a.dts:145 */
			cs-gpios = < &gpioa 0x2 0x11 >;                              /* in zephyr\boards\st\b_l4s5i_iot01a\b_l4s5i_iot01a.dts:146 */
			status = "okay";                                             /* in zephyr\boards\st\b_l4s5i_iot01a\b_l4s5i_iot01a.dts:147 */
		};

		/* node '/soc/timers@40012c00' defined in zephyr\dts\arm\st\l4\stm32l4.dtsi:297 */
		timers1: timers@40012c00 {
			compatible = "st,stm32-timers"; /* in zephyr\dts\arm\st\l4\stm32l4.dtsi:298 */
			reg = < 0x40012c00 0x400 >;     /* in zephyr\dts\arm\st\l4\stm32l4.dtsi:299 */
			clocks = < &rcc 0x60 0x800 >,
			         < &rcc 0x9 0xff >;     /* in zephyr\dts\arm\st\l4\stm32l4.dtsi:300 */
			resets = < &rctl 0x80b >;       /* in zephyr\dts\arm\st\l4\stm32l4.dtsi:302 */
			interrupts = < 0x18 0x0 >,
			             < 0x19 0x0 >,
			             < 0x1a 0x0 >,
			             < 0x1b 0x0 >;      /* in zephyr\dts\arm\st\l4\stm32l4.dtsi:303 */
			interrupt-names = "brk",
			                  "up",
			                  "trgcom",
			                  "cc";         /* in zephyr\dts\arm\st\l4\stm32l4.dtsi:304 */
			st,prescaler = < 0x0 >;         /* in zephyr\dts\arm\st\l4\stm32l4.dtsi:305 */
			status = "disabled";            /* in zephyr\dts\arm\st\l4\stm32l4.dtsi:306 */

			/* node '/soc/timers@40012c00/pwm' defined in zephyr\dts\arm\st\l4\stm32l4.dtsi:308 */
			pwm {
				compatible = "st,stm32-pwm"; /* in zephyr\dts\arm\st\l4\stm32l4.dtsi:309 */
				status = "disabled";         /* in zephyr\dts\arm\st\l4\stm32l4.dtsi:310 */
				#pwm-cells = < 0x3 >;        /* in zephyr\dts\arm\st\l4\stm32l4.dtsi:311 */
			};

			/* node '/soc/timers@40012c00/counter' defined in zephyr\dts\arm\st\l4\stm32l4.dtsi:314 */
			counter {
				compatible = "st,stm32-counter"; /* in zephyr\dts\arm\st\l4\stm32l4.dtsi:315 */
				status = "disabled";             /* in zephyr\dts\arm\st\l4\stm32l4.dtsi:316 */
			};

			/* node '/soc/timers@40012c00/qdec' defined in zephyr\dts\arm\st\l4\stm32l4.dtsi:319 */
			qdec {
				compatible = "st,stm32-qdec";    /* in zephyr\dts\arm\st\l4\stm32l4.dtsi:320 */
				st,input-filter-level = < 0x0 >; /* in zephyr\dts\arm\st\l4\stm32l4.dtsi:321 */
				status = "disabled";             /* in zephyr\dts\arm\st\l4\stm32l4.dtsi:322 */
			};
		};

		/* node '/soc/timers@40000000' defined in zephyr\dts\arm\st\l4\stm32l4.dtsi:326 */
		timers2: timers@40000000 {
			compatible = "st,stm32-timers"; /* in zephyr\dts\arm\st\l4\stm32l4.dtsi:327 */
			reg = < 0x40000000 0x400 >;     /* in zephyr\dts\arm\st\l4\stm32l4.dtsi:328 */
			clocks = < &rcc 0x58 0x1 >,
			         < &rcc 0x8 0xff >;     /* in zephyr\dts\arm\st\l4\stm32l4.dtsi:329 */
			resets = < &rctl 0x700 >;       /* in zephyr\dts\arm\st\l4\stm32l4.dtsi:331 */
			interrupts = < 0x1c 0x0 >;      /* in zephyr\dts\arm\st\l4\stm32l4.dtsi:332 */
			interrupt-names = "global";     /* in zephyr\dts\arm\st\l4\stm32l4.dtsi:333 */
			st,prescaler = < 0x0 >;         /* in zephyr\dts\arm\st\l4\stm32l4.dtsi:334 */
			status = "okay";                /* in zephyr\boards\st\b_l4s5i_iot01a\b_l4s5i_iot01a.dts:208 */

			/* node '/soc/timers@40000000/pwm' defined in zephyr\dts\arm\st\l4\stm32l4.dtsi:337 */
			pwm2: pwm {
				compatible = "st,stm32-pwm";    /* in zephyr\dts\arm\st\l4\stm32l4.dtsi:338 */
				#pwm-cells = < 0x3 >;           /* in zephyr\dts\arm\st\l4\stm32l4.dtsi:340 */
				status = "okay";                /* in zephyr\boards\st\b_l4s5i_iot01a\b_l4s5i_iot01a.dts:211 */
				pinctrl-0 = < &tim2_ch1_pa15 >; /* in zephyr\boards\st\b_l4s5i_iot01a\b_l4s5i_iot01a.dts:212 */
				pinctrl-names = "default";      /* in zephyr\boards\st\b_l4s5i_iot01a\b_l4s5i_iot01a.dts:213 */
			};

			/* node '/soc/timers@40000000/counter' defined in zephyr\dts\arm\st\l4\stm32l4.dtsi:343 */
			counter {
				compatible = "st,stm32-counter"; /* in zephyr\dts\arm\st\l4\stm32l4.dtsi:344 */
				status = "disabled";             /* in zephyr\dts\arm\st\l4\stm32l4.dtsi:345 */
			};

			/* node '/soc/timers@40000000/qdec' defined in zephyr\dts\arm\st\l4\stm32l4.dtsi:348 */
			qdec {
				compatible = "st,stm32-qdec";    /* in zephyr\dts\arm\st\l4\stm32l4.dtsi:349 */
				st,input-filter-level = < 0x0 >; /* in zephyr\dts\arm\st\l4\stm32l4.dtsi:350 */
				status = "disabled";             /* in zephyr\dts\arm\st\l4\stm32l4.dtsi:351 */
			};
		};

		/* node '/soc/timers@40001000' defined in zephyr\dts\arm\st\l4\stm32l4.dtsi:355 */
		timers6: timers@40001000 {
			compatible = "st,stm32-timers"; /* in zephyr\dts\arm\st\l4\stm32l4.dtsi:356 */
			reg = < 0x40001000 0x400 >;     /* in zephyr\dts\arm\st\l4\stm32l4.dtsi:357 */
			clocks = < &rcc 0x58 0x10 >,
			         < &rcc 0x8 0xff >;     /* in zephyr\dts\arm\st\l4\stm32l4.dtsi:358 */
			resets = < &rctl 0x704 >;       /* in zephyr\dts\arm\st\l4\stm32l4.dtsi:360 */
			interrupts = < 0x36 0x0 >;      /* in zephyr\dts\arm\st\l4\stm32l4.dtsi:361 */
			interrupt-names = "global";     /* in zephyr\dts\arm\st\l4\stm32l4.dtsi:362 */
			st,prescaler = < 0x0 >;         /* in zephyr\dts\arm\st\l4\stm32l4.dtsi:363 */
			status = "disabled";            /* in zephyr\dts\arm\st\l4\stm32l4.dtsi:364 */

			/* node '/soc/timers@40001000/counter' defined in zephyr\dts\arm\st\l4\stm32l4.dtsi:366 */
			counter {
				compatible = "st,stm32-counter"; /* in zephyr\dts\arm\st\l4\stm32l4.dtsi:367 */
				status = "disabled";             /* in zephyr\dts\arm\st\l4\stm32l4.dtsi:368 */
			};
		};

		/* node '/soc/timers@40014000' defined in zephyr\dts\arm\st\l4\stm32l4.dtsi:372 */
		timers15: timers@40014000 {
			compatible = "st,stm32-timers"; /* in zephyr\dts\arm\st\l4\stm32l4.dtsi:373 */
			reg = < 0x40014000 0x400 >;     /* in zephyr\dts\arm\st\l4\stm32l4.dtsi:374 */
			clocks = < &rcc 0x60 0x10000 >,
			         < &rcc 0x9 0xff >;     /* in zephyr\dts\arm\st\l4\stm32l4.dtsi:375 */
			resets = < &rctl 0x810 >;       /* in zephyr\dts\arm\st\l4\stm32l4.dtsi:377 */
			interrupts = < 0x18 0x0 >;      /* in zephyr\dts\arm\st\l4\stm32l4.dtsi:378 */
			interrupt-names = "global";     /* in zephyr\dts\arm\st\l4\stm32l4.dtsi:379 */
			st,prescaler = < 0x0 >;         /* in zephyr\dts\arm\st\l4\stm32l4.dtsi:380 */
			status = "disabled";            /* in zephyr\dts\arm\st\l4\stm32l4.dtsi:381 */

			/* node '/soc/timers@40014000/pwm' defined in zephyr\dts\arm\st\l4\stm32l4.dtsi:383 */
			pwm {
				compatible = "st,stm32-pwm"; /* in zephyr\dts\arm\st\l4\stm32l4.dtsi:384 */
				status = "disabled";         /* in zephyr\dts\arm\st\l4\stm32l4.dtsi:385 */
				#pwm-cells = < 0x3 >;        /* in zephyr\dts\arm\st\l4\stm32l4.dtsi:386 */
			};

			/* node '/soc/timers@40014000/counter' defined in zephyr\dts\arm\st\l4\stm32l4.dtsi:389 */
			counter {
				compatible = "st,stm32-counter"; /* in zephyr\dts\arm\st\l4\stm32l4.dtsi:390 */
				status = "disabled";             /* in zephyr\dts\arm\st\l4\stm32l4.dtsi:391 */
			};
		};

		/* node '/soc/timers@40014400' defined in zephyr\dts\arm\st\l4\stm32l4.dtsi:395 */
		timers16: timers@40014400 {
			compatible = "st,stm32-timers"; /* in zephyr\dts\arm\st\l4\stm32l4.dtsi:396 */
			reg = < 0x40014400 0x400 >;     /* in zephyr\dts\arm\st\l4\stm32l4.dtsi:397 */
			clocks = < &rcc 0x60 0x20000 >,
			         < &rcc 0x9 0xff >;     /* in zephyr\dts\arm\st\l4\stm32l4.dtsi:398 */
			resets = < &rctl 0x811 >;       /* in zephyr\dts\arm\st\l4\stm32l4.dtsi:400 */
			interrupts = < 0x19 0x0 >;      /* in zephyr\dts\arm\st\l4\stm32l4.dtsi:401 */
			interrupt-names = "global";     /* in zephyr\dts\arm\st\l4\stm32l4.dtsi:402 */
			st,prescaler = < 0x0 >;         /* in zephyr\dts\arm\st\l4\stm32l4.dtsi:403 */
			status = "disabled";            /* in zephyr\dts\arm\st\l4\stm32l4.dtsi:404 */

			/* node '/soc/timers@40014400/pwm' defined in zephyr\dts\arm\st\l4\stm32l4.dtsi:406 */
			pwm {
				compatible = "st,stm32-pwm"; /* in zephyr\dts\arm\st\l4\stm32l4.dtsi:407 */
				status = "disabled";         /* in zephyr\dts\arm\st\l4\stm32l4.dtsi:408 */
				#pwm-cells = < 0x3 >;        /* in zephyr\dts\arm\st\l4\stm32l4.dtsi:409 */
			};

			/* node '/soc/timers@40014400/counter' defined in zephyr\dts\arm\st\l4\stm32l4.dtsi:412 */
			counter {
				compatible = "st,stm32-counter"; /* in zephyr\dts\arm\st\l4\stm32l4.dtsi:413 */
				status = "disabled";             /* in zephyr\dts\arm\st\l4\stm32l4.dtsi:414 */
			};
		};

		/* node '/soc/rtc@40002800' defined in zephyr\dts\arm\st\l4\stm32l4.dtsi:418 */
		rtc: rtc@40002800 {
			compatible = "st,stm32-rtc";       /* in zephyr\dts\arm\st\l4\stm32l4.dtsi:419 */
			reg = < 0x40002800 0x400 >;        /* in zephyr\dts\arm\st\l4\stm32l4.dtsi:420 */
			interrupts = < 0x29 0x0 >;         /* in zephyr\dts\arm\st\l4\stm32l4.dtsi:421 */
			prescaler = < 0x8000 >;            /* in zephyr\dts\arm\st\l4\stm32l4.dtsi:423 */
			alarms-count = < 0x2 >;            /* in zephyr\dts\arm\st\l4\stm32l4.dtsi:424 */
			alrm-exti-line = < 0x12 >;         /* in zephyr\dts\arm\st\l4\stm32l4.dtsi:425 */
			clocks = < &rcc 0x58 0x10000000 >,
			         < &rcc 0x3 0x2280090 >;   /* in zephyr\boards\st\b_l4s5i_iot01a\b_l4s5i_iot01a.dts:218 */
			status = "okay";                   /* in zephyr\boards\st\b_l4s5i_iot01a\b_l4s5i_iot01a.dts:220 */

			/* node '/soc/rtc@40002800/backup_regs' defined in zephyr\dts\arm\st\l4\stm32l4r5.dtsi:32 */
			bbram: backup_regs {
				compatible = "st,stm32-bbram"; /* in zephyr\dts\arm\st\l4\stm32l4r5.dtsi:33 */
				st,backup-regs = < 0x20 >;     /* in zephyr\dts\arm\st\l4\stm32l4r5.dtsi:34 */
				status = "disabled";           /* in zephyr\dts\arm\st\l4\stm32l4r5.dtsi:35 */
			};
		};

		/* node '/soc/adc@50040000' defined in zephyr\dts\arm\st\l4\stm32l4.dtsi:429 */
		adc1: adc@50040000 {
			compatible = "st,stm32-adc";                                /* in zephyr\dts\arm\st\l4\stm32l4.dtsi:430 */
			reg = < 0x50040000 0x100 >;                                 /* in zephyr\dts\arm\st\l4\stm32l4.dtsi:431 */
			clocks = < &rcc 0x4c 0x2000 >;                              /* in zephyr\dts\arm\st\l4\stm32l4.dtsi:432 */
			clock-names = "adcx";                                       /* in zephyr\dts\arm\st\l4\stm32l4.dtsi:433 */
			interrupts = < 0x12 0x0 >;                                  /* in zephyr\dts\arm\st\l4\stm32l4.dtsi:434 */
			#io-channel-cells = < 0x1 >;                                /* in zephyr\dts\arm\st\l4\stm32l4.dtsi:435 */
			st,adc-resolutions = < 0xc 0xa 0x8 0x6 >;                   /* in zephyr\dts\arm\st\l4\stm32l4.dtsi:436 */
			sampling-times = < 0x3 0x7 0xd 0x19 0x30 0x5d 0xf8 0x281 >; /* in zephyr\dts\arm\st\l4\stm32l4.dtsi:437 */
			st,adc-sequencer = "programmable";                          /* in zephyr\dts\arm\st\l4\stm32l4.dtsi:438 */
			st,adc-oversampler = "minimal";                             /* in zephyr\dts\arm\st\l4\stm32l4.dtsi:439 */
			st,adc-internal-regulator = "startup-sw-delay";             /* in zephyr\dts\arm\st\l4\stm32l4.dtsi:440 */
			st,adc-has-deep-powerdown;                                  /* in zephyr\dts\arm\st\l4\stm32l4.dtsi:441 */
			st,adc-has-differential-support;                            /* in zephyr\dts\arm\st\l4\stm32l4.dtsi:442 */
			status = "okay";                                            /* in zephyr\samples\basic\app_test_7\b_l4s5i_iot01a.overlay:2 */
			pinctrl-0 = < &adc1_in1_pc0 >;                              /* in zephyr\samples\basic\app_test_7\b_l4s5i_iot01a.overlay:3 */
			pinctrl-names = "default";                                  /* in zephyr\samples\basic\app_test_7\b_l4s5i_iot01a.overlay:4 */
			st,adc-clock-source = "SYNC";                               /* in zephyr\samples\basic\app_test_7\b_l4s5i_iot01a.overlay:7 */
			st,adc-prescaler = < 0x2 >;                                 /* in zephyr\samples\basic\app_test_7\b_l4s5i_iot01a.overlay:8 */
			#address-cells = < 0x1 >;                                   /* in zephyr\samples\basic\app_test_7\b_l4s5i_iot01a.overlay:10 */
			#size-cells = < 0x0 >;                                      /* in zephyr\samples\basic\app_test_7\b_l4s5i_iot01a.overlay:11 */
			phandle = < 0x2a >;                                         /* in zephyr\dts\arm\st\l4\stm32l4.dtsi:560 */

			/* node '/soc/adc@50040000/channel@1' defined in zephyr\samples\basic\app_test_7\b_l4s5i_iot01a.overlay:13 */
			channel@1 {
				reg = < 0x1 >;                         /* in zephyr\samples\basic\app_test_7\b_l4s5i_iot01a.overlay:14 */
				zephyr,gain = "ADC_GAIN_1";            /* in zephyr\samples\basic\app_test_7\b_l4s5i_iot01a.overlay:15 */
				zephyr,reference = "ADC_REF_INTERNAL"; /* in zephyr\samples\basic\app_test_7\b_l4s5i_iot01a.overlay:16 */
				zephyr,acquisition-time = < 0x0 >;     /* in zephyr\samples\basic\app_test_7\b_l4s5i_iot01a.overlay:17 */
				zephyr,resolution = < 0xc >;           /* in zephyr\samples\basic\app_test_7\b_l4s5i_iot01a.overlay:18 */
			};
		};

		/* node '/soc/adc@50040100' defined in zephyr\dts\arm\st\l4\stm32l4.dtsi:446 */
		adc2: adc@50040100 {
			compatible = "st,stm32-adc";                                /* in zephyr\dts\arm\st\l4\stm32l4.dtsi:447 */
			reg = < 0x50040100 0x100 >;                                 /* in zephyr\dts\arm\st\l4\stm32l4.dtsi:448 */
			clocks = < &rcc 0x4c 0x2000 >;                              /* in zephyr\dts\arm\st\l4\stm32l4.dtsi:449 */
			clock-names = "adcx";                                       /* in zephyr\dts\arm\st\l4\stm32l4.dtsi:450 */
			interrupts = < 0x12 0x0 >;                                  /* in zephyr\dts\arm\st\l4\stm32l4.dtsi:451 */
			#io-channel-cells = < 0x1 >;                                /* in zephyr\dts\arm\st\l4\stm32l4.dtsi:452 */
			st,adc-resolutions = < 0xc 0xa 0x8 0x6 >;                   /* in zephyr\dts\arm\st\l4\stm32l4.dtsi:453 */
			sampling-times = < 0x3 0x7 0xd 0x19 0x30 0x5d 0xf8 0x281 >; /* in zephyr\dts\arm\st\l4\stm32l4.dtsi:454 */
			st,adc-sequencer = "programmable";                          /* in zephyr\dts\arm\st\l4\stm32l4.dtsi:455 */
			st,adc-oversampler = "minimal";                             /* in zephyr\dts\arm\st\l4\stm32l4.dtsi:456 */
			st,adc-internal-regulator = "startup-sw-delay";             /* in zephyr\dts\arm\st\l4\stm32l4.dtsi:457 */
			st,adc-has-deep-powerdown;                                  /* in zephyr\dts\arm\st\l4\stm32l4.dtsi:458 */
			st,adc-has-differential-support;                            /* in zephyr\dts\arm\st\l4\stm32l4.dtsi:459 */
			status = "disabled";                                        /* in zephyr\dts\arm\st\l4\stm32l4.dtsi:460 */
		};

		/* node '/soc/dma@40020000' defined in zephyr\dts\arm\st\l4\stm32l4.dtsi:463 */
		dma1: dma@40020000 {
			compatible = "st,stm32-dma-v2";                                             /* in zephyr\dts\arm\st\l4\stm32l4.dtsi:464 */
			#dma-cells = < 0x3 >;                                                       /* in zephyr\dts\arm\st\l4\stm32l4.dtsi:465 */
			reg = < 0x40020000 0x400 >;                                                 /* in zephyr\dts\arm\st\l4\stm32l4.dtsi:466 */
			interrupts = < 0xb 0x0 0xc 0x0 0xd 0x0 0xe 0x0 0xf 0x0 0x10 0x0 0x11 0x0 >; /* in zephyr\dts\arm\st\l4\stm32l4.dtsi:467 */
			clocks = < &rcc 0x48 0x1 >;                                                 /* in zephyr\dts\arm\st\l4\stm32l4.dtsi:468 */
			dma-requests = < 0x7 >;                                                     /* in zephyr\dts\arm\st\l4\stm32l4.dtsi:469 */
			dma-offset = < 0x0 >;                                                       /* in zephyr\dts\arm\st\l4\stm32l4p5.dtsi:369 */
			status = "okay";                                                            /* in zephyr\boards\st\b_l4s5i_iot01a\b_l4s5i_iot01a.dts:274 */
			phandle = < 0x1f >;                                                         /* in zephyr\dts\arm\st\l4\stm32l4r5.dtsi:40 */
		};

		/* node '/soc/dma@40020400' defined in zephyr\dts\arm\st\l4\stm32l4.dtsi:473 */
		dma2: dma@40020400 {
			compatible = "st,stm32-dma-v2";                                                  /* in zephyr\dts\arm\st\l4\stm32l4.dtsi:474 */
			#dma-cells = < 0x3 >;                                                            /* in zephyr\dts\arm\st\l4\stm32l4.dtsi:475 */
			reg = < 0x40020400 0x400 >;                                                      /* in zephyr\dts\arm\st\l4\stm32l4.dtsi:476 */
			interrupts = < 0x38 0x0 0x39 0x0 0x3a 0x0 0x3b 0x0 0x3c 0x0 0x44 0x0 0x45 0x0 >; /* in zephyr\dts\arm\st\l4\stm32l4.dtsi:477 */
			clocks = < &rcc 0x48 0x2 >;                                                      /* in zephyr\dts\arm\st\l4\stm32l4.dtsi:478 */
			dma-requests = < 0x7 >;                                                          /* in zephyr\dts\arm\st\l4\stm32l4.dtsi:479 */
			status = "disabled";                                                             /* in zephyr\dts\arm\st\l4\stm32l4.dtsi:480 */
			dma-offset = < 0x7 >;                                                            /* in zephyr\dts\arm\st\l4\stm32l4p5.dtsi:373 */
			phandle = < 0xf >;                                                               /* in zephyr\dts\arm\st\l4\stm32l4_sai.dtsi:16 */
		};

		/* node '/soc/timers@40007c00' defined in zephyr\dts\arm\st\l4\stm32l4.dtsi:483 */
		lptim1: timers@40007c00 {
			compatible = "st,stm32-lptim";     /* in zephyr\dts\arm\st\l4\stm32l4.dtsi:484 */
			clocks = < &rcc 0x58 0x80000000 >; /* in zephyr\dts\arm\st\l4\stm32l4.dtsi:485 */
			resets = < &rctl 0x71f >;          /* in zephyr\dts\arm\st\l4\stm32l4.dtsi:486 */
			#address-cells = < 0x1 >;          /* in zephyr\dts\arm\st\l4\stm32l4.dtsi:487 */
			#size-cells = < 0x0 >;             /* in zephyr\dts\arm\st\l4\stm32l4.dtsi:488 */
			reg = < 0x40007c00 0x400 >;        /* in zephyr\dts\arm\st\l4\stm32l4.dtsi:489 */
			interrupts = < 0x41 0x1 >;         /* in zephyr\dts\arm\st\l4\stm32l4.dtsi:490 */
			interrupt-names = "wakeup";        /* in zephyr\dts\arm\st\l4\stm32l4.dtsi:491 */
			status = "disabled";               /* in zephyr\dts\arm\st\l4\stm32l4.dtsi:492 */
		};

		/* node '/soc/timers@40009400' defined in zephyr\dts\arm\st\l4\stm32l4.dtsi:495 */
		lptim2: timers@40009400 {
			compatible = "st,stm32-lptim"; /* in zephyr\dts\arm\st\l4\stm32l4.dtsi:496 */
			#address-cells = < 0x1 >;      /* in zephyr\dts\arm\st\l4\stm32l4.dtsi:497 */
			#size-cells = < 0x0 >;         /* in zephyr\dts\arm\st\l4\stm32l4.dtsi:498 */
			reg = < 0x40009400 0x400 >;    /* in zephyr\dts\arm\st\l4\stm32l4.dtsi:499 */
			clocks = < &rcc 0x5c 0x20 >;   /* in zephyr\dts\arm\st\l4\stm32l4.dtsi:500 */
			resets = < &rctl 0x785 >;      /* in zephyr\dts\arm\st\l4\stm32l4.dtsi:501 */
			interrupts = < 0x42 0x1 >;     /* in zephyr\dts\arm\st\l4\stm32l4.dtsi:502 */
			interrupt-names = "wakeup";    /* in zephyr\dts\arm\st\l4\stm32l4.dtsi:503 */
			status = "disabled";           /* in zephyr\dts\arm\st\l4\stm32l4.dtsi:504 */
		};

		/* node '/soc/rng@50060800' defined in zephyr\dts\arm\st\l4\stm32l4.dtsi:507 */
		rng: rng@50060800 {
			compatible = "st,stm32-rng";    /* in zephyr\dts\arm\st\l4\stm32l4.dtsi:508 */
			reg = < 0x50060800 0x400 >;     /* in zephyr\dts\arm\st\l4\stm32l4.dtsi:509 */
			interrupts = < 0x50 0x0 >;      /* in zephyr\dts\arm\st\l4\stm32l4.dtsi:510 */
			clocks = < &rcc 0x4c 0x40000 >,
			         < &rcc 0x5 0x3a0088 >; /* in zephyr\dts\arm\st\l4\stm32l4p5.dtsi:62 */
			status = "okay";                /* in zephyr\boards\st\b_l4s5i_iot01a\b_l4s5i_iot01a.dts:235 */
		};

		/* node '/soc/power@40007000' defined in zephyr\dts\arm\st\l4\stm32l4.dtsi:519 */
		pwr: power@40007000 {
			compatible = "st,stm32-pwr"; /* in zephyr\dts\arm\st\l4\stm32l4.dtsi:520 */
			reg = < 0x40007000 0x400 >;  /* in zephyr\dts\arm\st\l4\stm32l4.dtsi:521 */
			status = "disabled";         /* in zephyr\dts\arm\st\l4\stm32l4.dtsi:522 */
			wkup-pins-nb = < 0x5 >;      /* in zephyr\dts\arm\st\l4\stm32l4.dtsi:524 */
			wkup-pins-pol;               /* in zephyr\dts\arm\st\l4\stm32l4.dtsi:525 */
			wkup-pins-pupd;              /* in zephyr\dts\arm\st\l4\stm32l4.dtsi:526 */
			#address-cells = < 0x1 >;    /* in zephyr\dts\arm\st\l4\stm32l4.dtsi:528 */
			#size-cells = < 0x0 >;       /* in zephyr\dts\arm\st\l4\stm32l4.dtsi:529 */

			/* node '/soc/power@40007000/wkup-pin@1' defined in zephyr\dts\arm\st\l4\stm32l4.dtsi:531 */
			wkup-pin@1 {
				reg = < 0x1 >; /* in zephyr\dts\arm\st\l4\stm32l4.dtsi:532 */
			};

			/* node '/soc/power@40007000/wkup-pin@2' defined in zephyr\dts\arm\st\l4\stm32l4.dtsi:535 */
			wkup-pin@2 {
				reg = < 0x2 >; /* in zephyr\dts\arm\st\l4\stm32l4.dtsi:536 */
			};

			/* node '/soc/power@40007000/wkup-pin@3' defined in zephyr\dts\arm\st\l4\stm32l4.dtsi:539 */
			wkup-pin@3 {
				reg = < 0x3 >; /* in zephyr\dts\arm\st\l4\stm32l4.dtsi:540 */
			};

			/* node '/soc/power@40007000/wkup-pin@4' defined in zephyr\dts\arm\st\l4\stm32l4.dtsi:543 */
			wkup-pin@4 {
				reg = < 0x4 >; /* in zephyr\dts\arm\st\l4\stm32l4.dtsi:544 */
			};

			/* node '/soc/power@40007000/wkup-pin@5' defined in zephyr\dts\arm\st\l4\stm32l4.dtsi:547 */
			wkup-pin@5 {
				reg = < 0x5 >; /* in zephyr\dts\arm\st\l4\stm32l4.dtsi:548 */
			};
		};

		/* node '/soc/sai1@40015404' defined in zephyr\dts\arm\st\l4\stm32l4_sai.dtsi:9 */
		sai1_a: sai1@40015404 {
			compatible = "st,stm32-sai";      /* in zephyr\dts\arm\st\l4\stm32l4_sai.dtsi:10 */
			#address-cells = < 0x1 >;         /* in zephyr\dts\arm\st\l4\stm32l4_sai.dtsi:11 */
			#size-cells = < 0x0 >;            /* in zephyr\dts\arm\st\l4\stm32l4_sai.dtsi:12 */
			reg = < 0x40015404 0x20 >;        /* in zephyr\dts\arm\st\l4\stm32l4_sai.dtsi:13 */
			clocks = < &rcc 0x60 0x200000 >,
			         < &rcc 0xd 0x360088 >;   /* in zephyr\dts\arm\st\l4\stm32l4_sai.dtsi:14 */
			dmas = < &dma2 0x1 0x1 0x22800 >; /* in zephyr\dts\arm\st\l4\stm32l4_sai.dtsi:16 */
			status = "disabled";              /* in zephyr\dts\arm\st\l4\stm32l4_sai.dtsi:18 */
		};

		/* node '/soc/sai1@40015424' defined in zephyr\dts\arm\st\l4\stm32l4_sai.dtsi:21 */
		sai1_b: sai1@40015424 {
			compatible = "st,stm32-sai";      /* in zephyr\dts\arm\st\l4\stm32l4_sai.dtsi:22 */
			#address-cells = < 0x1 >;         /* in zephyr\dts\arm\st\l4\stm32l4_sai.dtsi:23 */
			#size-cells = < 0x0 >;            /* in zephyr\dts\arm\st\l4\stm32l4_sai.dtsi:24 */
			reg = < 0x40015424 0x20 >;        /* in zephyr\dts\arm\st\l4\stm32l4_sai.dtsi:25 */
			clocks = < &rcc 0x60 0x200000 >,
			         < &rcc 0xd 0x360088 >;   /* in zephyr\dts\arm\st\l4\stm32l4_sai.dtsi:26 */
			dmas = < &dma2 0x2 0x1 0x22800 >; /* in zephyr\dts\arm\st\l4\stm32l4_sai.dtsi:28 */
			status = "disabled";              /* in zephyr\dts\arm\st\l4\stm32l4_sai.dtsi:30 */
		};

		/* node '/soc/serial@40004800' defined in zephyr\dts\arm\st\l4\stm32l4p5.dtsi:110 */
		usart3: serial@40004800 {
			compatible = "st,stm32-usart",
			             "st,stm32-uart";   /* in zephyr\dts\arm\st\l4\stm32l4p5.dtsi:111 */
			reg = < 0x40004800 0x400 >;     /* in zephyr\dts\arm\st\l4\stm32l4p5.dtsi:112 */
			clocks = < &rcc 0x58 0x40000 >; /* in zephyr\dts\arm\st\l4\stm32l4p5.dtsi:113 */
			resets = < &rctl 0x712 >;       /* in zephyr\dts\arm\st\l4\stm32l4p5.dtsi:114 */
			interrupts = < 0x27 0x0 >;      /* in zephyr\dts\arm\st\l4\stm32l4p5.dtsi:115 */
			status = "disabled";            /* in zephyr\dts\arm\st\l4\stm32l4p5.dtsi:116 */
		};

		/* node '/soc/serial@40004c00' defined in zephyr\dts\arm\st\l4\stm32l4p5.dtsi:119 */
		uart4: arduino_serial: serial@40004c00 {
			compatible = "st,stm32-uart";                /* in zephyr\dts\arm\st\l4\stm32l4p5.dtsi:120 */
			reg = < 0x40004c00 0x400 >;                  /* in zephyr\dts\arm\st\l4\stm32l4p5.dtsi:121 */
			clocks = < &rcc 0x58 0x80000 >;              /* in zephyr\dts\arm\st\l4\stm32l4p5.dtsi:122 */
			resets = < &rctl 0x713 >;                    /* in zephyr\dts\arm\st\l4\stm32l4p5.dtsi:123 */
			interrupts = < 0x34 0x0 >;                   /* in zephyr\dts\arm\st\l4\stm32l4p5.dtsi:124 */
			status = "disabled";                         /* in zephyr\dts\arm\st\l4\stm32l4p5.dtsi:125 */
			pinctrl-0 = < &uart4_tx_pa0 &uart4_rx_pa1 >; /* in zephyr\boards\st\b_l4s5i_iot01a\b_l4s5i_iot01a.dts:97 */
			pinctrl-names = "default";                   /* in zephyr\boards\st\b_l4s5i_iot01a\b_l4s5i_iot01a.dts:98 */
			current-speed = < 0x1c200 >;                 /* in zephyr\boards\st\b_l4s5i_iot01a\b_l4s5i_iot01a.dts:99 */
		};

		/* node '/soc/serial@40005000' defined in zephyr\dts\arm\st\l4\stm32l4p5.dtsi:128 */
		uart5: serial@40005000 {
			compatible = "st,stm32-uart";    /* in zephyr\dts\arm\st\l4\stm32l4p5.dtsi:129 */
			reg = < 0x40005000 0x400 >;      /* in zephyr\dts\arm\st\l4\stm32l4p5.dtsi:130 */
			clocks = < &rcc 0x58 0x100000 >; /* in zephyr\dts\arm\st\l4\stm32l4p5.dtsi:131 */
			resets = < &rctl 0x714 >;        /* in zephyr\dts\arm\st\l4\stm32l4p5.dtsi:132 */
			interrupts = < 0x35 0x0 >;       /* in zephyr\dts\arm\st\l4\stm32l4p5.dtsi:133 */
			status = "disabled";             /* in zephyr\dts\arm\st\l4\stm32l4p5.dtsi:134 */
		};

		/* node '/soc/i2c@40005800' defined in zephyr\dts\arm\st\l4\stm32l4p5.dtsi:137 */
		i2c2: i2c@40005800 {
			compatible = "st,stm32-i2c-v2";                /* in zephyr\dts\arm\st\l4\stm32l4p5.dtsi:138 */
			#address-cells = < 0x1 >;                      /* in zephyr\dts\arm\st\l4\stm32l4p5.dtsi:140 */
			#size-cells = < 0x0 >;                         /* in zephyr\dts\arm\st\l4\stm32l4p5.dtsi:141 */
			reg = < 0x40005800 0x400 >;                    /* in zephyr\dts\arm\st\l4\stm32l4p5.dtsi:142 */
			clocks = < &rcc 0x58 0x400000 >;               /* in zephyr\dts\arm\st\l4\stm32l4p5.dtsi:143 */
			interrupts = < 0x21 0x0 >,
			             < 0x22 0x0 >;                     /* in zephyr\dts\arm\st\l4\stm32l4p5.dtsi:144 */
			interrupt-names = "event",
			                  "error";                     /* in zephyr\dts\arm\st\l4\stm32l4p5.dtsi:145 */
			pinctrl-0 = < &i2c2_scl_pb10 &i2c2_sda_pb11 >; /* in zephyr\boards\st\b_l4s5i_iot01a\b_l4s5i_iot01a.dts:110 */
			pinctrl-names = "default";                     /* in zephyr\boards\st\b_l4s5i_iot01a\b_l4s5i_iot01a.dts:111 */
			status = "okay";                               /* in zephyr\boards\st\b_l4s5i_iot01a\b_l4s5i_iot01a.dts:112 */
			clock-frequency = < 0x61a80 >;                 /* in zephyr\boards\st\b_l4s5i_iot01a\b_l4s5i_iot01a.dts:113 */
			phandle = < 0x2d >;                            /* in zephyr\dts\arm\st\l4\stm32l4p5.dtsi:475 */

			/* node '/soc/i2c@40005800/lis3mdl-magn@1e' defined in zephyr\boards\st\b_l4s5i_iot01a\b_l4s5i_iot01a.dts:115 */
			lis3mdl-magn@1e {
				compatible = "st,lis3mdl-magn"; /* in zephyr\boards\st\b_l4s5i_iot01a\b_l4s5i_iot01a.dts:116 */
				reg = < 0x1e >;                 /* in zephyr\boards\st\b_l4s5i_iot01a\b_l4s5i_iot01a.dts:117 */
			};

			/* node '/soc/i2c@40005800/hts221@5f' defined in zephyr\boards\st\b_l4s5i_iot01a\b_l4s5i_iot01a.dts:120 */
			hts221@5f {
				compatible = "st,hts221"; /* in zephyr\boards\st\b_l4s5i_iot01a\b_l4s5i_iot01a.dts:121 */
				reg = < 0x5f >;           /* in zephyr\boards\st\b_l4s5i_iot01a\b_l4s5i_iot01a.dts:122 */
			};

			/* node '/soc/i2c@40005800/lps22hb-press@5d' defined in zephyr\boards\st\b_l4s5i_iot01a\b_l4s5i_iot01a.dts:125 */
			lps22hb-press@5d {
				compatible = "st,lps22hb-press"; /* in zephyr\boards\st\b_l4s5i_iot01a\b_l4s5i_iot01a.dts:126 */
				reg = < 0x5d >;                  /* in zephyr\boards\st\b_l4s5i_iot01a\b_l4s5i_iot01a.dts:127 */
			};

			/* node '/soc/i2c@40005800/lsm6dsl@6a' defined in zephyr\boards\st\b_l4s5i_iot01a\b_l4s5i_iot01a.dts:130 */
			lsm6dsl: lsm6dsl@6a {
				compatible = "st,lsm6dsl";      /* in zephyr\boards\st\b_l4s5i_iot01a\b_l4s5i_iot01a.dts:131 */
				reg = < 0x6a >;                 /* in zephyr\boards\st\b_l4s5i_iot01a\b_l4s5i_iot01a.dts:132 */
				irq-gpios = < &gpiod 0xb 0x0 >; /* in zephyr\boards\st\b_l4s5i_iot01a\b_l4s5i_iot01a.dts:133 */
			};

			/* node '/soc/i2c@40005800/vl53l0x@29' defined in zephyr\boards\st\b_l4s5i_iot01a\b_l4s5i_iot01a.dts:136 */
			vl53l0x@29 {
				compatible = "st,vl53l0x";        /* in zephyr\boards\st\b_l4s5i_iot01a\b_l4s5i_iot01a.dts:137 */
				reg = < 0x29 >;                   /* in zephyr\boards\st\b_l4s5i_iot01a\b_l4s5i_iot01a.dts:138 */
				xshut-gpios = < &gpioc 0x6 0x1 >; /* in zephyr\boards\st\b_l4s5i_iot01a\b_l4s5i_iot01a.dts:139 */
			};
		};

		/* node '/soc/i2c@40008400' defined in zephyr\dts\arm\st\l4\stm32l4p5.dtsi:149 */
		i2c4: i2c@40008400 {
			compatible = "st,stm32-i2c-v2"; /* in zephyr\dts\arm\st\l4\stm32l4p5.dtsi:150 */
			clock-frequency = < 0x186a0 >;  /* in zephyr\dts\arm\st\l4\stm32l4p5.dtsi:151 */
			#address-cells = < 0x1 >;       /* in zephyr\dts\arm\st\l4\stm32l4p5.dtsi:152 */
			#size-cells = < 0x0 >;          /* in zephyr\dts\arm\st\l4\stm32l4p5.dtsi:153 */
			reg = < 0x40008400 0x400 >;     /* in zephyr\dts\arm\st\l4\stm32l4p5.dtsi:154 */
			clocks = < &rcc 0x5c 0x2 >;     /* in zephyr\dts\arm\st\l4\stm32l4p5.dtsi:155 */
			interrupts = < 0x54 0x0 >,
			             < 0x53 0x0 >;      /* in zephyr\dts\arm\st\l4\stm32l4p5.dtsi:156 */
			interrupt-names = "event",
			                  "error";      /* in zephyr\dts\arm\st\l4\stm32l4p5.dtsi:157 */
			status = "disabled";            /* in zephyr\dts\arm\st\l4\stm32l4p5.dtsi:158 */
			phandle = < 0x2e >;             /* in zephyr\dts\arm\st\l4\stm32l4p5.dtsi:483 */
		};

		/* node '/soc/spi@40003800' defined in zephyr\dts\arm\st\l4\stm32l4p5.dtsi:161 */
		spi2: spi@40003800 {
			compatible = "st,stm32-spi-fifo",
			             "st,stm32-spi";            /* in zephyr\dts\arm\st\l4\stm32l4p5.dtsi:162 */
			#address-cells = < 0x1 >;               /* in zephyr\dts\arm\st\l4\stm32l4p5.dtsi:163 */
			#size-cells = < 0x0 >;                  /* in zephyr\dts\arm\st\l4\stm32l4p5.dtsi:164 */
			reg = < 0x40003800 0x400 >;             /* in zephyr\dts\arm\st\l4\stm32l4p5.dtsi:165 */
			clocks = < &rcc 0x58 0x4000 >;          /* in zephyr\dts\arm\st\l4\stm32l4p5.dtsi:166 */
			interrupts = < 0x24 0x5 >;              /* in zephyr\dts\arm\st\l4\stm32l4p5.dtsi:167 */
			st,spi-data-width = "full-4-to-16-bit"; /* in zephyr\dts\arm\st\l4\stm32l4p5.dtsi:168 */
			status = "disabled";                    /* in zephyr\dts\arm\st\l4\stm32l4p5.dtsi:169 */
		};

		/* node '/soc/spi@40003c00' defined in zephyr\dts\arm\st\l4\stm32l4p5.dtsi:172 */
		spi3: spi@40003c00 {
			compatible = "st,stm32-spi-fifo",
			             "st,stm32-spi";                                    /* in zephyr\dts\arm\st\l4\stm32l4p5.dtsi:173 */
			#address-cells = < 0x1 >;                                       /* in zephyr\dts\arm\st\l4\stm32l4p5.dtsi:174 */
			#size-cells = < 0x0 >;                                          /* in zephyr\dts\arm\st\l4\stm32l4p5.dtsi:175 */
			reg = < 0x40003c00 0x400 >;                                     /* in zephyr\dts\arm\st\l4\stm32l4p5.dtsi:176 */
			clocks = < &rcc 0x58 0x8000 >;                                  /* in zephyr\dts\arm\st\l4\stm32l4p5.dtsi:177 */
			interrupts = < 0x33 0x5 >;                                      /* in zephyr\dts\arm\st\l4\stm32l4p5.dtsi:178 */
			st,spi-data-width = "full-4-to-16-bit";                         /* in zephyr\dts\arm\st\l4\stm32l4p5.dtsi:179 */
			pinctrl-0 = < &spi3_sck_pc10 &spi3_miso_pc11 &spi3_mosi_pc12 >; /* in zephyr\boards\st\b_l4s5i_iot01a\b_l4s5i_iot01a.dts:151 */
			pinctrl-names = "default";                                      /* in zephyr\boards\st\b_l4s5i_iot01a\b_l4s5i_iot01a.dts:152 */
			status = "okay";                                                /* in zephyr\boards\st\b_l4s5i_iot01a\b_l4s5i_iot01a.dts:153 */
			cs-gpios = < &gpiod 0xd 0x1 >,
			           < &gpioe 0x0 0x1 >;                                  /* in zephyr\boards\st\b_l4s5i_iot01a\b_l4s5i_iot01a.dts:155 */

			/* node '/soc/spi@40003c00/spbtle-rf@0' defined in zephyr\boards\st\b_l4s5i_iot01a\b_l4s5i_iot01a.dts:158 */
			hci_spi: spbtle-rf@0 {
				compatible = "st,hci-spi-v1";     /* in zephyr\boards\st\b_l4s5i_iot01a\b_l4s5i_iot01a.dts:159 */
				reg = < 0x0 >;                    /* in zephyr\boards\st\b_l4s5i_iot01a\b_l4s5i_iot01a.dts:160 */
				reset-gpios = < &gpioa 0x8 0x1 >; /* in zephyr\boards\st\b_l4s5i_iot01a\b_l4s5i_iot01a.dts:161 */
				irq-gpios = < &gpioe 0x6 0x20 >;  /* in zephyr\boards\st\b_l4s5i_iot01a\b_l4s5i_iot01a.dts:162 */
				spi-max-frequency = < 0x1e8480 >; /* in zephyr\boards\st\b_l4s5i_iot01a\b_l4s5i_iot01a.dts:163 */
				spi-hold-cs;                      /* in zephyr\boards\st\b_l4s5i_iot01a\b_l4s5i_iot01a.dts:164 */
			};

			/* node '/soc/spi@40003c00/ism43362@1' defined in zephyr\boards\st\b_l4s5i_iot01a\b_l4s5i_iot01a.dts:167 */
			wifi0: ism43362@1 {
				compatible = "inventek,eswifi";    /* in zephyr\boards\st\b_l4s5i_iot01a\b_l4s5i_iot01a.dts:168 */
				spi-max-frequency = < 0x1e8480 >;  /* in zephyr\boards\st\b_l4s5i_iot01a\b_l4s5i_iot01a.dts:169 */
				reg = < 0x1 >;                     /* in zephyr\boards\st\b_l4s5i_iot01a\b_l4s5i_iot01a.dts:170 */
				resetn-gpios = < &gpioe 0x8 0x0 >; /* in zephyr\boards\st\b_l4s5i_iot01a\b_l4s5i_iot01a.dts:171 */
				boot0-gpios = < &gpiob 0xc 0x0 >;  /* in zephyr\boards\st\b_l4s5i_iot01a\b_l4s5i_iot01a.dts:172 */
				wakeup-gpios = < &gpiob 0xd 0x0 >; /* in zephyr\boards\st\b_l4s5i_iot01a\b_l4s5i_iot01a.dts:173 */
				data-gpios = < &gpioe 0x1 0x0 >;   /* in zephyr\boards\st\b_l4s5i_iot01a\b_l4s5i_iot01a.dts:174 */
			};
		};

		/* node '/soc/timers@40000400' defined in zephyr\dts\arm\st\l4\stm32l4p5.dtsi:183 */
		timers3: timers@40000400 {
			compatible = "st,stm32-timers"; /* in zephyr\dts\arm\st\l4\stm32l4p5.dtsi:184 */
			reg = < 0x40000400 0x400 >;     /* in zephyr\dts\arm\st\l4\stm32l4p5.dtsi:185 */
			clocks = < &rcc 0x58 0x2 >,
			         < &rcc 0x8 0xff >;     /* in zephyr\dts\arm\st\l4\stm32l4p5.dtsi:186 */
			resets = < &rctl 0x701 >;       /* in zephyr\dts\arm\st\l4\stm32l4p5.dtsi:188 */
			interrupts = < 0x1d 0x0 >;      /* in zephyr\dts\arm\st\l4\stm32l4p5.dtsi:189 */
			interrupt-names = "global";     /* in zephyr\dts\arm\st\l4\stm32l4p5.dtsi:190 */
			st,prescaler = < 0x0 >;         /* in zephyr\dts\arm\st\l4\stm32l4p5.dtsi:191 */
			status = "disabled";            /* in zephyr\dts\arm\st\l4\stm32l4p5.dtsi:192 */

			/* node '/soc/timers@40000400/pwm' defined in zephyr\dts\arm\st\l4\stm32l4p5.dtsi:194 */
			pwm {
				compatible = "st,stm32-pwm"; /* in zephyr\dts\arm\st\l4\stm32l4p5.dtsi:195 */
				status = "disabled";         /* in zephyr\dts\arm\st\l4\stm32l4p5.dtsi:196 */
				#pwm-cells = < 0x3 >;        /* in zephyr\dts\arm\st\l4\stm32l4p5.dtsi:197 */
			};

			/* node '/soc/timers@40000400/counter' defined in zephyr\dts\arm\st\l4\stm32l4p5.dtsi:200 */
			counter {
				compatible = "st,stm32-counter"; /* in zephyr\dts\arm\st\l4\stm32l4p5.dtsi:201 */
				status = "disabled";             /* in zephyr\dts\arm\st\l4\stm32l4p5.dtsi:202 */
			};

			/* node '/soc/timers@40000400/qdec' defined in zephyr\dts\arm\st\l4\stm32l4p5.dtsi:205 */
			qdec {
				compatible = "st,stm32-qdec";    /* in zephyr\dts\arm\st\l4\stm32l4p5.dtsi:206 */
				st,input-filter-level = < 0x0 >; /* in zephyr\dts\arm\st\l4\stm32l4p5.dtsi:207 */
				status = "disabled";             /* in zephyr\dts\arm\st\l4\stm32l4p5.dtsi:208 */
			};
		};

		/* node '/soc/timers@40000800' defined in zephyr\dts\arm\st\l4\stm32l4p5.dtsi:212 */
		timers4: timers@40000800 {
			compatible = "st,stm32-timers"; /* in zephyr\dts\arm\st\l4\stm32l4p5.dtsi:213 */
			reg = < 0x40000800 0x400 >;     /* in zephyr\dts\arm\st\l4\stm32l4p5.dtsi:214 */
			clocks = < &rcc 0x58 0x4 >,
			         < &rcc 0x8 0xff >;     /* in zephyr\dts\arm\st\l4\stm32l4p5.dtsi:215 */
			resets = < &rctl 0x702 >;       /* in zephyr\dts\arm\st\l4\stm32l4p5.dtsi:217 */
			interrupts = < 0x1e 0x0 >;      /* in zephyr\dts\arm\st\l4\stm32l4p5.dtsi:218 */
			interrupt-names = "global";     /* in zephyr\dts\arm\st\l4\stm32l4p5.dtsi:219 */
			st,prescaler = < 0x0 >;         /* in zephyr\dts\arm\st\l4\stm32l4p5.dtsi:220 */
			status = "disabled";            /* in zephyr\dts\arm\st\l4\stm32l4p5.dtsi:221 */

			/* node '/soc/timers@40000800/pwm' defined in zephyr\dts\arm\st\l4\stm32l4p5.dtsi:223 */
			pwm {
				compatible = "st,stm32-pwm"; /* in zephyr\dts\arm\st\l4\stm32l4p5.dtsi:224 */
				status = "disabled";         /* in zephyr\dts\arm\st\l4\stm32l4p5.dtsi:225 */
				#pwm-cells = < 0x3 >;        /* in zephyr\dts\arm\st\l4\stm32l4p5.dtsi:226 */
			};

			/* node '/soc/timers@40000800/counter' defined in zephyr\dts\arm\st\l4\stm32l4p5.dtsi:229 */
			counter {
				compatible = "st,stm32-counter"; /* in zephyr\dts\arm\st\l4\stm32l4p5.dtsi:230 */
				status = "disabled";             /* in zephyr\dts\arm\st\l4\stm32l4p5.dtsi:231 */
			};

			/* node '/soc/timers@40000800/qdec' defined in zephyr\dts\arm\st\l4\stm32l4p5.dtsi:234 */
			qdec {
				compatible = "st,stm32-qdec";    /* in zephyr\dts\arm\st\l4\stm32l4p5.dtsi:235 */
				st,input-filter-level = < 0x0 >; /* in zephyr\dts\arm\st\l4\stm32l4p5.dtsi:236 */
				status = "disabled";             /* in zephyr\dts\arm\st\l4\stm32l4p5.dtsi:237 */
			};
		};

		/* node '/soc/timers@40000c00' defined in zephyr\dts\arm\st\l4\stm32l4p5.dtsi:241 */
		timers5: timers@40000c00 {
			compatible = "st,stm32-timers"; /* in zephyr\dts\arm\st\l4\stm32l4p5.dtsi:242 */
			reg = < 0x40000c00 0x400 >;     /* in zephyr\dts\arm\st\l4\stm32l4p5.dtsi:243 */
			clocks = < &rcc 0x58 0x8 >,
			         < &rcc 0x8 0xff >;     /* in zephyr\dts\arm\st\l4\stm32l4p5.dtsi:244 */
			resets = < &rctl 0x703 >;       /* in zephyr\dts\arm\st\l4\stm32l4p5.dtsi:246 */
			interrupts = < 0x32 0x0 >;      /* in zephyr\dts\arm\st\l4\stm32l4p5.dtsi:247 */
			interrupt-names = "global";     /* in zephyr\dts\arm\st\l4\stm32l4p5.dtsi:248 */
			st,prescaler = < 0x0 >;         /* in zephyr\dts\arm\st\l4\stm32l4p5.dtsi:249 */
			status = "disabled";            /* in zephyr\dts\arm\st\l4\stm32l4p5.dtsi:250 */

			/* node '/soc/timers@40000c00/pwm' defined in zephyr\dts\arm\st\l4\stm32l4p5.dtsi:252 */
			pwm {
				compatible = "st,stm32-pwm"; /* in zephyr\dts\arm\st\l4\stm32l4p5.dtsi:253 */
				status = "disabled";         /* in zephyr\dts\arm\st\l4\stm32l4p5.dtsi:254 */
				#pwm-cells = < 0x3 >;        /* in zephyr\dts\arm\st\l4\stm32l4p5.dtsi:255 */
			};

			/* node '/soc/timers@40000c00/counter' defined in zephyr\dts\arm\st\l4\stm32l4p5.dtsi:258 */
			counter {
				compatible = "st,stm32-counter"; /* in zephyr\dts\arm\st\l4\stm32l4p5.dtsi:259 */
				status = "disabled";             /* in zephyr\dts\arm\st\l4\stm32l4p5.dtsi:260 */
			};

			/* node '/soc/timers@40000c00/qdec' defined in zephyr\dts\arm\st\l4\stm32l4p5.dtsi:263 */
			qdec {
				compatible = "st,stm32-qdec";    /* in zephyr\dts\arm\st\l4\stm32l4p5.dtsi:264 */
				st,input-filter-level = < 0x0 >; /* in zephyr\dts\arm\st\l4\stm32l4p5.dtsi:265 */
				status = "disabled";             /* in zephyr\dts\arm\st\l4\stm32l4p5.dtsi:266 */
			};
		};

		/* node '/soc/timers@40001400' defined in zephyr\dts\arm\st\l4\stm32l4p5.dtsi:270 */
		timers7: timers@40001400 {
			compatible = "st,stm32-timers"; /* in zephyr\dts\arm\st\l4\stm32l4p5.dtsi:271 */
			reg = < 0x40001400 0x400 >;     /* in zephyr\dts\arm\st\l4\stm32l4p5.dtsi:272 */
			clocks = < &rcc 0x58 0x20 >,
			         < &rcc 0x8 0xff >;     /* in zephyr\dts\arm\st\l4\stm32l4p5.dtsi:273 */
			resets = < &rctl 0x705 >;       /* in zephyr\dts\arm\st\l4\stm32l4p5.dtsi:275 */
			interrupts = < 0x37 0x0 >;      /* in zephyr\dts\arm\st\l4\stm32l4p5.dtsi:276 */
			interrupt-names = "global";     /* in zephyr\dts\arm\st\l4\stm32l4p5.dtsi:277 */
			st,prescaler = < 0x0 >;         /* in zephyr\dts\arm\st\l4\stm32l4p5.dtsi:278 */
			status = "disabled";            /* in zephyr\dts\arm\st\l4\stm32l4p5.dtsi:279 */

			/* node '/soc/timers@40001400/pwm' defined in zephyr\dts\arm\st\l4\stm32l4p5.dtsi:281 */
			pwm {
				compatible = "st,stm32-pwm"; /* in zephyr\dts\arm\st\l4\stm32l4p5.dtsi:282 */
				status = "disabled";         /* in zephyr\dts\arm\st\l4\stm32l4p5.dtsi:283 */
				#pwm-cells = < 0x3 >;        /* in zephyr\dts\arm\st\l4\stm32l4p5.dtsi:284 */
			};

			/* node '/soc/timers@40001400/counter' defined in zephyr\dts\arm\st\l4\stm32l4p5.dtsi:287 */
			counter {
				compatible = "st,stm32-counter"; /* in zephyr\dts\arm\st\l4\stm32l4p5.dtsi:288 */
				status = "disabled";             /* in zephyr\dts\arm\st\l4\stm32l4p5.dtsi:289 */
			};
		};

		/* node '/soc/timers@40013400' defined in zephyr\dts\arm\st\l4\stm32l4p5.dtsi:293 */
		timers8: timers@40013400 {
			compatible = "st,stm32-timers"; /* in zephyr\dts\arm\st\l4\stm32l4p5.dtsi:294 */
			reg = < 0x40013400 0x400 >;     /* in zephyr\dts\arm\st\l4\stm32l4p5.dtsi:295 */
			clocks = < &rcc 0x60 0x2000 >,
			         < &rcc 0x9 0xff >;     /* in zephyr\dts\arm\st\l4\stm32l4p5.dtsi:296 */
			resets = < &rctl 0x80d >;       /* in zephyr\dts\arm\st\l4\stm32l4p5.dtsi:298 */
			interrupts = < 0x2b 0x0 >,
			             < 0x2c 0x0 >,
			             < 0x2d 0x0 >,
			             < 0x2e 0x0 >;      /* in zephyr\dts\arm\st\l4\stm32l4p5.dtsi:299 */
			interrupt-names = "brk",
			                  "up",
			                  "trgcom",
			                  "cc";         /* in zephyr\dts\arm\st\l4\stm32l4p5.dtsi:300 */
			st,prescaler = < 0x0 >;         /* in zephyr\dts\arm\st\l4\stm32l4p5.dtsi:301 */
			status = "disabled";            /* in zephyr\dts\arm\st\l4\stm32l4p5.dtsi:302 */

			/* node '/soc/timers@40013400/pwm' defined in zephyr\dts\arm\st\l4\stm32l4p5.dtsi:304 */
			pwm {
				compatible = "st,stm32-pwm"; /* in zephyr\dts\arm\st\l4\stm32l4p5.dtsi:305 */
				status = "disabled";         /* in zephyr\dts\arm\st\l4\stm32l4p5.dtsi:306 */
				#pwm-cells = < 0x3 >;        /* in zephyr\dts\arm\st\l4\stm32l4p5.dtsi:307 */
			};

			/* node '/soc/timers@40013400/counter' defined in zephyr\dts\arm\st\l4\stm32l4p5.dtsi:310 */
			counter {
				compatible = "st,stm32-counter"; /* in zephyr\dts\arm\st\l4\stm32l4p5.dtsi:311 */
				status = "disabled";             /* in zephyr\dts\arm\st\l4\stm32l4p5.dtsi:312 */
			};

			/* node '/soc/timers@40013400/qdec' defined in zephyr\dts\arm\st\l4\stm32l4p5.dtsi:315 */
			qdec {
				compatible = "st,stm32-qdec";    /* in zephyr\dts\arm\st\l4\stm32l4p5.dtsi:316 */
				st,input-filter-level = < 0x0 >; /* in zephyr\dts\arm\st\l4\stm32l4p5.dtsi:317 */
				status = "disabled";             /* in zephyr\dts\arm\st\l4\stm32l4p5.dtsi:318 */
			};
		};

		/* node '/soc/timers@40014800' defined in zephyr\dts\arm\st\l4\stm32l4p5.dtsi:322 */
		timers17: timers@40014800 {
			compatible = "st,stm32-timers"; /* in zephyr\dts\arm\st\l4\stm32l4p5.dtsi:323 */
			reg = < 0x40014800 0x400 >;     /* in zephyr\dts\arm\st\l4\stm32l4p5.dtsi:324 */
			clocks = < &rcc 0x60 0x40000 >,
			         < &rcc 0x9 0xff >;     /* in zephyr\dts\arm\st\l4\stm32l4p5.dtsi:325 */
			resets = < &rctl 0x812 >;       /* in zephyr\dts\arm\st\l4\stm32l4p5.dtsi:327 */
			interrupts = < 0x1a 0x0 >;      /* in zephyr\dts\arm\st\l4\stm32l4p5.dtsi:328 */
			interrupt-names = "global";     /* in zephyr\dts\arm\st\l4\stm32l4p5.dtsi:329 */
			st,prescaler = < 0x0 >;         /* in zephyr\dts\arm\st\l4\stm32l4p5.dtsi:330 */
			status = "disabled";            /* in zephyr\dts\arm\st\l4\stm32l4p5.dtsi:331 */

			/* node '/soc/timers@40014800/pwm' defined in zephyr\dts\arm\st\l4\stm32l4p5.dtsi:333 */
			pwm {
				compatible = "st,stm32-pwm"; /* in zephyr\dts\arm\st\l4\stm32l4p5.dtsi:334 */
				status = "disabled";         /* in zephyr\dts\arm\st\l4\stm32l4p5.dtsi:335 */
				#pwm-cells = < 0x3 >;        /* in zephyr\dts\arm\st\l4\stm32l4p5.dtsi:336 */
			};

			/* node '/soc/timers@40014800/counter' defined in zephyr\dts\arm\st\l4\stm32l4p5.dtsi:339 */
			counter {
				compatible = "st,stm32-counter"; /* in zephyr\dts\arm\st\l4\stm32l4p5.dtsi:340 */
				status = "disabled";             /* in zephyr\dts\arm\st\l4\stm32l4p5.dtsi:341 */
			};
		};

		/* node '/soc/can@40006400' defined in zephyr\dts\arm\st\l4\stm32l4p5.dtsi:345 */
		can1: can@40006400 {
			compatible = "st,stm32-bxcan";    /* in zephyr\dts\arm\st\l4\stm32l4p5.dtsi:346 */
			reg = < 0x40006400 0x400 >;       /* in zephyr\dts\arm\st\l4\stm32l4p5.dtsi:347 */
			interrupts = < 0x13 0x0 >,
			             < 0x14 0x0 >,
			             < 0x15 0x0 >,
			             < 0x16 0x0 >;        /* in zephyr\dts\arm\st\l4\stm32l4p5.dtsi:348 */
			interrupt-names = "TX",
			                  "RX0",
			                  "RX1",
			                  "SCE";          /* in zephyr\dts\arm\st\l4\stm32l4p5.dtsi:349 */
			clocks = < &rcc 0x58 0x2000000 >; /* in zephyr\dts\arm\st\l4\stm32l4p5.dtsi:350 */
			status = "disabled";              /* in zephyr\dts\arm\st\l4\stm32l4p5.dtsi:351 */
		};

		/* node '/soc/otgfs@50000000' defined in zephyr\dts\arm\st\l4\stm32l4p5.dtsi:354 */
		usbotg_fs: zephyr_udc0: otgfs@50000000 {
			compatible = "st,stm32-otgfs";                                               /* in zephyr\dts\arm\st\l4\stm32l4p5.dtsi:355 */
			reg = < 0x50000000 0x40000 >;                                                /* in zephyr\dts\arm\st\l4\stm32l4p5.dtsi:356 */
			interrupts = < 0x43 0x0 >;                                                   /* in zephyr\dts\arm\st\l4\stm32l4p5.dtsi:357 */
			interrupt-names = "otgfs";                                                   /* in zephyr\dts\arm\st\l4\stm32l4p5.dtsi:358 */
			num-bidir-endpoints = < 0x6 >;                                               /* in zephyr\dts\arm\st\l4\stm32l4p5.dtsi:359 */
			ram-size = < 0x500 >;                                                        /* in zephyr\dts\arm\st\l4\stm32l4p5.dtsi:360 */
			maximum-speed = "full-speed";                                                /* in zephyr\dts\arm\st\l4\stm32l4p5.dtsi:361 */
			clocks = < &rcc 0x4c 0x1000 >,
			         < &rcc 0x5 0x3a0088 >;                                              /* in zephyr\dts\arm\st\l4\stm32l4p5.dtsi:362 */
			phys = < &otgfs_phy >;                                                       /* in zephyr\dts\arm\st\l4\stm32l4p5.dtsi:364 */
			pinctrl-0 = < &usb_otg_fs_dm_pa11 &usb_otg_fs_dp_pa12 &usb_otg_fs_id_pa10 >; /* in zephyr\boards\st\b_l4s5i_iot01a\b_l4s5i_iot01a.dts:224 */
			pinctrl-names = "default";                                                   /* in zephyr\boards\st\b_l4s5i_iot01a\b_l4s5i_iot01a.dts:226 */
			status = "okay";                                                             /* in zephyr\boards\st\b_l4s5i_iot01a\b_l4s5i_iot01a.dts:227 */
		};

		/* node '/soc/dmamux@40020800' defined in zephyr\dts\arm\st\l4\stm32l4p5.dtsi:376 */
		dmamux1: dmamux@40020800 {
			compatible = "st,stm32-dmamux"; /* in zephyr\dts\arm\st\l4\stm32l4p5.dtsi:377 */
			#dma-cells = < 0x3 >;           /* in zephyr\dts\arm\st\l4\stm32l4p5.dtsi:378 */
			reg = < 0x40020800 0x400 >;     /* in zephyr\dts\arm\st\l4\stm32l4p5.dtsi:379 */
			interrupts = < 0x5e 0x0 >;      /* in zephyr\dts\arm\st\l4\stm32l4p5.dtsi:380 */
			clocks = < &rcc 0x48 0x4 >;     /* in zephyr\dts\arm\st\l4\stm32l4p5.dtsi:381 */
			dma-channels = < 0xe >;         /* in zephyr\dts\arm\st\l4\stm32l4p5.dtsi:382 */
			dma-generators = < 0x4 >;       /* in zephyr\dts\arm\st\l4\stm32l4p5.dtsi:383 */
			dma-requests = < 0x59 >;        /* in zephyr\dts\arm\st\l4\stm32l4p5.dtsi:384 */
			status = "okay";                /* in zephyr\boards\st\b_l4s5i_iot01a\b_l4s5i_iot01a.dts:278 */
		};

		/* node '/soc/dcmi@50050000' defined in zephyr\dts\arm\st\l4\stm32l4p5.dtsi:388 */
		dcmi: dcmi@50050000 {
			compatible = "st,stm32-dcmi";          /* in zephyr\dts\arm\st\l4\stm32l4p5.dtsi:389 */
			reg = < 0x50050000 0x400 >;            /* in zephyr\dts\arm\st\l4\stm32l4p5.dtsi:390 */
			interrupts = < 0x55 0x0 >;             /* in zephyr\dts\arm\st\l4\stm32l4p5.dtsi:391 */
			interrupt-names = "dcmi";              /* in zephyr\dts\arm\st\l4\stm32l4p5.dtsi:392 */
			clocks = < &rcc 0x4c 0x4000 >;         /* in zephyr\dts\arm\st\l4\stm32l4p5.dtsi:393 */
			status = "disabled";                   /* in zephyr\dts\arm\st\l4\stm32l4p5.dtsi:398 */
			dmas = < &dma1 0x1 0x5a 0x24480 0x0 >; /* in zephyr\dts\arm\st\l4\stm32l4r5.dtsi:40 */
		};

		/* node '/soc/sdmmc@50062400' defined in zephyr\dts\arm\st\l4\stm32l4p5.dtsi:401 */
		sdmmc1: sdmmc@50062400 {
			compatible = "st,stm32-sdmmc";   /* in zephyr\dts\arm\st\l4\stm32l4p5.dtsi:402 */
			reg = < 0x50062400 0x400 >;      /* in zephyr\dts\arm\st\l4\stm32l4p5.dtsi:403 */
			clocks = < &rcc 0x4c 0x400000 >,
			         < &rcc 0x5 0x3a0088 >;  /* in zephyr\dts\arm\st\l4\stm32l4p5.dtsi:404 */
			resets = < &rctl 0x596 >;        /* in zephyr\dts\arm\st\l4\stm32l4p5.dtsi:406 */
			interrupts = < 0x31 0x0 >;       /* in zephyr\dts\arm\st\l4\stm32l4p5.dtsi:407 */
			idma;                            /* in zephyr\dts\arm\st\l4\stm32l4p5.dtsi:408 */
			status = "disabled";             /* in zephyr\dts\arm\st\l4\stm32l4p5.dtsi:409 */
		};

		/* node '/soc/dac@40007400' defined in zephyr\dts\arm\st\l4\stm32l4p5.dtsi:423 */
		dac1: dac@40007400 {
			compatible = "st,stm32-dac";       /* in zephyr\dts\arm\st\l4\stm32l4p5.dtsi:424 */
			reg = < 0x40007400 0x400 >;        /* in zephyr\dts\arm\st\l4\stm32l4p5.dtsi:425 */
			clocks = < &rcc 0x58 0x20000000 >; /* in zephyr\dts\arm\st\l4\stm32l4p5.dtsi:426 */
			status = "disabled";               /* in zephyr\dts\arm\st\l4\stm32l4p5.dtsi:427 */
			#io-channel-cells = < 0x1 >;       /* in zephyr\dts\arm\st\l4\stm32l4p5.dtsi:428 */
		};

		/* node '/soc/spi@a0001000' defined in zephyr\dts\arm\st\l4\stm32l4p5.dtsi:431 */
		octospi1: spi@a0001000 {
			compatible = "st,stm32-ospi";                                                                         /* in zephyr\dts\arm\st\l4\stm32l4p5.dtsi:432 */
			reg = < 0xa0001000 0x400 >,
			      < 0x90000000 0x10000000 >;                                                                      /* in zephyr\dts\arm\st\l4\stm32l4p5.dtsi:433 */
			interrupts = < 0x47 0x0 >;                                                                            /* in zephyr\dts\arm\st\l4\stm32l4p5.dtsi:434 */
			clock-names = "ospix",
			              "ospi-ker",
			              "ospi-mgr";                                                                             /* in zephyr\dts\arm\st\l4\stm32l4p5.dtsi:435 */
			clocks = < &rcc 0x50 0x100 >,
			         < &rcc 0x1 0x34009c >,
			         < &rcc 0x4c 0x100000 >;                                                                      /* in zephyr\dts\arm\st\l4\stm32l4p5.dtsi:436 */
			#address-cells = < 0x1 >;                                                                             /* in zephyr\dts\arm\st\l4\stm32l4p5.dtsi:440 */
			#size-cells = < 0x0 >;                                                                                /* in zephyr\dts\arm\st\l4\stm32l4p5.dtsi:441 */
			pinctrl-0 = < &octospim_p1_clk_pe10 &octospim_p1_ncs_pe11 &octospim_p1_io0_pe12 &octospim_p1_io1_pe13
			              &octospim_p1_io2_pe14 &octospim_p1_io3_pe15 >;                                          /* in zephyr\boards\st\b_l4s5i_iot01a\b_l4s5i_iot01a.dts:239 */
			pinctrl-names = "default";                                                                            /* in zephyr\boards\st\b_l4s5i_iot01a\b_l4s5i_iot01a.dts:242 */
			dmas = < &dma1 0x0 0x28 0x480 >;                                                                      /* in zephyr\boards\st\b_l4s5i_iot01a\b_l4s5i_iot01a.dts:244 */
			dma-names = "tx_rx";                                                                                  /* in zephyr\boards\st\b_l4s5i_iot01a\b_l4s5i_iot01a.dts:245 */
			status = "okay";                                                                                      /* in zephyr\boards\st\b_l4s5i_iot01a\b_l4s5i_iot01a.dts:247 */

			/* node '/soc/spi@a0001000/ospi-nor-flash@0' defined in zephyr\boards\st\b_l4s5i_iot01a\b_l4s5i_iot01a.dts:249 */
			mx25r6435f: ospi-nor-flash@0 {
				compatible = "st,stm32-ospi-nor";   /* in zephyr\boards\st\b_l4s5i_iot01a\b_l4s5i_iot01a.dts:250 */
				reg = < 0x0 >;                      /* in zephyr\boards\st\b_l4s5i_iot01a\b_l4s5i_iot01a.dts:251 */
				size = < 0x4000000 >;               /* in zephyr\boards\st\b_l4s5i_iot01a\b_l4s5i_iot01a.dts:252 */
				ospi-max-frequency = < 0x18cba80 >; /* in zephyr\boards\st\b_l4s5i_iot01a\b_l4s5i_iot01a.dts:253 */
				spi-bus-width = < 0x4 >;            /* in zephyr\boards\st\b_l4s5i_iot01a\b_l4s5i_iot01a.dts:254 */
				data-rate = < 0x1 >;                /* in zephyr\boards\st\b_l4s5i_iot01a\b_l4s5i_iot01a.dts:255 */
				writeoc = "PP_1_4_4";               /* in zephyr\boards\st\b_l4s5i_iot01a\b_l4s5i_iot01a.dts:256 */
				status = "okay";                    /* in zephyr\boards\st\b_l4s5i_iot01a\b_l4s5i_iot01a.dts:258 */

				/* node '/soc/spi@a0001000/ospi-nor-flash@0/partitions' defined in zephyr\boards\st\b_l4s5i_iot01a\b_l4s5i_iot01a.dts:260 */
				partitions {
					compatible = "fixed-partitions"; /* in zephyr\boards\st\b_l4s5i_iot01a\b_l4s5i_iot01a.dts:261 */
					#address-cells = < 0x1 >;        /* in zephyr\boards\st\b_l4s5i_iot01a\b_l4s5i_iot01a.dts:262 */
					#size-cells = < 0x1 >;           /* in zephyr\boards\st\b_l4s5i_iot01a\b_l4s5i_iot01a.dts:263 */

					/* node '/soc/spi@a0001000/ospi-nor-flash@0/partitions/partition@0' defined in zephyr\boards\st\b_l4s5i_iot01a\b_l4s5i_iot01a.dts:265 */
					store_partition: partition@0 {
						label = "store";        /* in zephyr\boards\st\b_l4s5i_iot01a\b_l4s5i_iot01a.dts:266 */
						reg = < 0x0 0x800000 >; /* in zephyr\boards\st\b_l4s5i_iot01a\b_l4s5i_iot01a.dts:267 */
					};
				};
			};
		};

		/* node '/soc/spi@a0001400' defined in zephyr\dts\arm\st\l4\stm32l4p5.dtsi:445 */
		octospi2: spi@a0001400 {
			compatible = "st,stm32-ospi";    /* in zephyr\dts\arm\st\l4\stm32l4p5.dtsi:446 */
			reg = < 0xa0001400 0x400 >,
			      < 0x70000000 0x10000000 >; /* in zephyr\dts\arm\st\l4\stm32l4p5.dtsi:447 */
			interrupts = < 0x4c 0x0 >;       /* in zephyr\dts\arm\st\l4\stm32l4p5.dtsi:448 */
			clock-names = "ospix",
			              "ospi-ker",
			              "ospi-mgr";        /* in zephyr\dts\arm\st\l4\stm32l4p5.dtsi:449 */
			clocks = < &rcc 0x50 0x200 >,
			         < &rcc 0x1 0x34009c >,
			         < &rcc 0x4c 0x100000 >; /* in zephyr\dts\arm\st\l4\stm32l4p5.dtsi:450 */
			#address-cells = < 0x1 >;        /* in zephyr\dts\arm\st\l4\stm32l4p5.dtsi:454 */
			#size-cells = < 0x0 >;           /* in zephyr\dts\arm\st\l4\stm32l4p5.dtsi:455 */
			status = "disabled";             /* in zephyr\dts\arm\st\l4\stm32l4p5.dtsi:456 */
		};

		/* node '/soc/aes@50060000' defined in zephyr\dts\arm\st\l4\stm32l4s5.dtsi:13 */
		aes: aes@50060000 {
			compatible = "st,stm32l4-aes",
			             "st,stm32-aes";    /* in zephyr\dts\arm\st\l4\stm32l4s5.dtsi:14 */
			reg = < 0x50060000 0x400 >;     /* in zephyr\dts\arm\st\l4\stm32l4s5.dtsi:15 */
			clocks = < &rcc 0x4c 0x10000 >; /* in zephyr\dts\arm\st\l4\stm32l4s5.dtsi:16 */
			resets = < &rctl 0x590 >;       /* in zephyr\dts\arm\st\l4\stm32l4s5.dtsi:17 */
			interrupts = < 0x4f 0x0 >;      /* in zephyr\dts\arm\st\l4\stm32l4s5.dtsi:18 */
			interrupt-names = "aes";        /* in zephyr\dts\arm\st\l4\stm32l4s5.dtsi:19 */
			status = "disabled";            /* in zephyr\dts\arm\st\l4\stm32l4s5.dtsi:20 */
		};
	};

	/* node '/cpus' defined in zephyr\dts\arm\st\l4\stm32l4.dtsi:29 */
	cpus {
		#address-cells = < 0x1 >; /* in zephyr\dts\arm\st\l4\stm32l4.dtsi:30 */
		#size-cells = < 0x0 >;    /* in zephyr\dts\arm\st\l4\stm32l4.dtsi:31 */

		/* node '/cpus/cpu@0' defined in zephyr\dts\arm\st\l4\stm32l4.dtsi:33 */
		cpu0: cpu@0 {
			device_type = "cpu";                         /* in zephyr\dts\arm\st\l4\stm32l4.dtsi:34 */
			compatible = "arm,cortex-m4f";               /* in zephyr\dts\arm\st\l4\stm32l4.dtsi:35 */
			reg = < 0x0 >;                               /* in zephyr\dts\arm\st\l4\stm32l4.dtsi:36 */
			cpu-power-states = < &stop0 &stop1 &stop2 >; /* in zephyr\dts\arm\st\l4\stm32l4.dtsi:37 */
		};

		/* node '/cpus/power-states' defined in zephyr\dts\arm\st\l4\stm32l4.dtsi:40 */
		power-states {

			/* node '/cpus/power-states/state0' defined in zephyr\dts\arm\st\l4\stm32l4.dtsi:41 */
			stop0: state0 {
				compatible = "zephyr,power-state";    /* in zephyr\dts\arm\st\l4\stm32l4.dtsi:42 */
				power-state-name = "suspend-to-idle"; /* in zephyr\dts\arm\st\l4\stm32l4.dtsi:43 */
				substate-id = < 0x1 >;                /* in zephyr\dts\arm\st\l4\stm32l4.dtsi:44 */
				min-residency-us = < 0x1f4 >;         /* in zephyr\dts\arm\st\l4\stm32l4.dtsi:45 */
				phandle = < 0x26 >;                   /* in zephyr\dts\arm\st\l4\stm32l4.dtsi:37 */
			};

			/* node '/cpus/power-states/state1' defined in zephyr\dts\arm\st\l4\stm32l4.dtsi:48 */
			stop1: state1 {
				compatible = "zephyr,power-state";    /* in zephyr\dts\arm\st\l4\stm32l4.dtsi:49 */
				power-state-name = "suspend-to-idle"; /* in zephyr\dts\arm\st\l4\stm32l4.dtsi:50 */
				substate-id = < 0x2 >;                /* in zephyr\dts\arm\st\l4\stm32l4.dtsi:51 */
				min-residency-us = < 0x2bc >;         /* in zephyr\dts\arm\st\l4\stm32l4.dtsi:52 */
				phandle = < 0x27 >;                   /* in zephyr\dts\arm\st\l4\stm32l4.dtsi:37 */
			};

			/* node '/cpus/power-states/state2' defined in zephyr\dts\arm\st\l4\stm32l4.dtsi:55 */
			stop2: state2 {
				compatible = "zephyr,power-state";    /* in zephyr\dts\arm\st\l4\stm32l4.dtsi:56 */
				power-state-name = "suspend-to-idle"; /* in zephyr\dts\arm\st\l4\stm32l4.dtsi:57 */
				substate-id = < 0x3 >;                /* in zephyr\dts\arm\st\l4\stm32l4.dtsi:58 */
				min-residency-us = < 0x3e8 >;         /* in zephyr\dts\arm\st\l4\stm32l4.dtsi:59 */
				phandle = < 0x28 >;                   /* in zephyr\dts\arm\st\l4\stm32l4.dtsi:37 */
			};
		};
	};

	/* node '/memory@20000000' defined in zephyr\dts\arm\st\l4\stm32l4.dtsi:64 */
	sram0: memory@20000000 {
		compatible = "zephyr,memory-region",
		             "mmio-sram";            /* in zephyr\dts\arm\st\l4\stm32l4.dtsi:65 */
		zephyr,memory-region = "SRAM0";      /* in zephyr\dts\arm\st\l4\stm32l4.dtsi:66 */
		reg = < 0x20000000 0x30000 >;        /* in zephyr\dts\arm\st\l4\stm32l4r5.dtsi:15 */
	};

	/* node '/clocks' defined in zephyr\dts\arm\st\l4\stm32l4.dtsi:69 */
	clocks {

		/* node '/clocks/clk-hse' defined in zephyr\dts\arm\st\l4\stm32l4.dtsi:70 */
		clk_hse: clk-hse {
			#clock-cells = < 0x0 >;            /* in zephyr\dts\arm\st\l4\stm32l4.dtsi:71 */
			compatible = "st,stm32-hse-clock"; /* in zephyr\dts\arm\st\l4\stm32l4.dtsi:72 */
			status = "disabled";               /* in zephyr\dts\arm\st\l4\stm32l4.dtsi:73 */
		};

		/* node '/clocks/clk-hsi' defined in zephyr\dts\arm\st\l4\stm32l4.dtsi:76 */
		clk_hsi: clk-hsi {
			#clock-cells = < 0x0 >;         /* in zephyr\dts\arm\st\l4\stm32l4.dtsi:77 */
			compatible = "fixed-clock";     /* in zephyr\dts\arm\st\l4\stm32l4.dtsi:78 */
			clock-frequency = < 0xf42400 >; /* in zephyr\dts\arm\st\l4\stm32l4.dtsi:79 */
			status = "okay";                /* in zephyr\boards\st\b_l4s5i_iot01a\b_l4s5i_iot01a.dts:69 */
			phandle = < 0x29 >;             /* in zephyr\boards\st\b_l4s5i_iot01a\b_l4s5i_iot01a.dts:77 */
		};

		/* node '/clocks/clk-msi' defined in zephyr\dts\arm\st\l4\stm32l4.dtsi:83 */
		clk_msi: clk-msi {
			#clock-cells = < 0x0 >;            /* in zephyr\dts\arm\st\l4\stm32l4.dtsi:84 */
			compatible = "st,stm32-msi-clock"; /* in zephyr\dts\arm\st\l4\stm32l4.dtsi:85 */
			msi-range = < 0x6 >;               /* in zephyr\dts\arm\st\l4\stm32l4.dtsi:86 */
			status = "disabled";               /* in zephyr\dts\arm\st\l4\stm32l4.dtsi:87 */
		};

		/* node '/clocks/clk-lse' defined in zephyr\dts\arm\st\l4\stm32l4.dtsi:90 */
		clk_lse: clk-lse {
			#clock-cells = < 0x0 >;            /* in zephyr\dts\arm\st\l4\stm32l4.dtsi:91 */
			compatible = "st,stm32-lse-clock"; /* in zephyr\dts\arm\st\l4\stm32l4.dtsi:92 */
			clock-frequency = < 0x8000 >;      /* in zephyr\dts\arm\st\l4\stm32l4.dtsi:93 */
			driving-capability = < 0x0 >;      /* in zephyr\dts\arm\st\l4\stm32l4.dtsi:94 */
			status = "disabled";               /* in zephyr\dts\arm\st\l4\stm32l4.dtsi:95 */
		};

		/* node '/clocks/clk-lsi' defined in zephyr\dts\arm\st\l4\stm32l4.dtsi:98 */
		clk_lsi: clk-lsi {
			#clock-cells = < 0x0 >;       /* in zephyr\dts\arm\st\l4\stm32l4.dtsi:99 */
			compatible = "fixed-clock";   /* in zephyr\dts\arm\st\l4\stm32l4.dtsi:100 */
			clock-frequency = < 0x7d00 >; /* in zephyr\dts\arm\st\l4\stm32l4.dtsi:101 */
			status = "okay";              /* in zephyr\boards\st\b_l4s5i_iot01a\b_l4s5i_iot01a.dts:61 */
		};

		/* node '/clocks/pll' defined in zephyr\dts\arm\st\l4\stm32l4.dtsi:105 */
		pll: pll {
			#clock-cells = < 0x0 >;              /* in zephyr\dts\arm\st\l4\stm32l4.dtsi:106 */
			compatible = "st,stm32l4-pll-clock"; /* in zephyr\dts\arm\st\l4\stm32l4.dtsi:107 */
			div-m = < 0x4 >;                     /* in zephyr\boards\st\b_l4s5i_iot01a\b_l4s5i_iot01a.dts:73 */
			mul-n = < 0x28 >;                    /* in zephyr\boards\st\b_l4s5i_iot01a\b_l4s5i_iot01a.dts:74 */
			div-q = < 0x2 >;                     /* in zephyr\boards\st\b_l4s5i_iot01a\b_l4s5i_iot01a.dts:75 */
			div-r = < 0x2 >;                     /* in zephyr\boards\st\b_l4s5i_iot01a\b_l4s5i_iot01a.dts:76 */
			clocks = < &clk_hsi >;               /* in zephyr\boards\st\b_l4s5i_iot01a\b_l4s5i_iot01a.dts:77 */
			status = "okay";                     /* in zephyr\boards\st\b_l4s5i_iot01a\b_l4s5i_iot01a.dts:78 */
			phandle = < 0x3 >;                   /* in zephyr\boards\st\b_l4s5i_iot01a\b_l4s5i_iot01a.dts:82 */
		};

		/* node '/clocks/pllsai1' defined in zephyr\dts\arm\st\l4\stm32l4.dtsi:111 */
		pllsai1: pllsai1 {
			#clock-cells = < 0x0 >;              /* in zephyr\dts\arm\st\l4\stm32l4.dtsi:112 */
			compatible = "st,stm32l4-pll-clock"; /* in zephyr\dts\arm\st\l4\stm32l4.dtsi:113 */
			status = "disabled";                 /* in zephyr\dts\arm\st\l4\stm32l4.dtsi:114 */
		};

		/* node '/clocks/clk-hsi48' defined in zephyr\dts\arm\st\l4\stm32l4p5.dtsi:34 */
		clk_hsi48: clk-hsi48 {
			#clock-cells = < 0x0 >;          /* in zephyr\dts\arm\st\l4\stm32l4p5.dtsi:35 */
			compatible = "fixed-clock";      /* in zephyr\dts\arm\st\l4\stm32l4p5.dtsi:36 */
			clock-frequency = < 0x2dc6c00 >; /* in zephyr\dts\arm\st\l4\stm32l4p5.dtsi:37 */
			status = "okay";                 /* in zephyr\boards\st\b_l4s5i_iot01a\b_l4s5i_iot01a.dts:65 */
		};

		/* node '/clocks/pllsai2' defined in zephyr\dts\arm\st\l4\stm32l4p5.dtsi:41 */
		pllsai2: pllsai2 {
			#clock-cells = < 0x0 >;              /* in zephyr\dts\arm\st\l4\stm32l4p5.dtsi:42 */
			compatible = "st,stm32l4-pll-clock"; /* in zephyr\dts\arm\st\l4\stm32l4p5.dtsi:43 */
			status = "disabled";                 /* in zephyr\dts\arm\st\l4\stm32l4p5.dtsi:44 */
		};
	};

	/* node '/mcos' defined in zephyr\dts\arm\st\l4\stm32l4.dtsi:118 */
	mcos {

		/* node '/mcos/mco1' defined in zephyr\dts\arm\st\l4\stm32l4.dtsi:119 */
		mco1: mco1 {
			compatible = "st,stm32-clock-mco"; /* in zephyr\dts\arm\st\l4\stm32l4.dtsi:120 */
			status = "disabled";               /* in zephyr\dts\arm\st\l4\stm32l4.dtsi:121 */
		};
	};

	/* node '/dietemp' defined in zephyr\dts\arm\st\l4\stm32l4.dtsi:553 */
	die_temp: dietemp {
		compatible = "st,stm32-temp-cal"; /* in zephyr\dts\arm\st\l4\stm32l4.dtsi:554 */
		ts-cal1-addr = < 0x1fff75a8 >;    /* in zephyr\dts\arm\st\l4\stm32l4.dtsi:555 */
		ts-cal2-addr = < 0x1fff75ca >;    /* in zephyr\dts\arm\st\l4\stm32l4.dtsi:556 */
		ts-cal1-temp = < 0x1e >;          /* in zephyr\dts\arm\st\l4\stm32l4.dtsi:557 */
		ts-cal2-temp = < 0x82 >;          /* in zephyr\dts\arm\st\l4\stm32l4.dtsi:558 */
		ts-cal-vrefanalog = < 0xbb8 >;    /* in zephyr\dts\arm\st\l4\stm32l4.dtsi:559 */
		io-channels = < &adc1 0x11 >;     /* in zephyr\dts\arm\st\l4\stm32l4.dtsi:560 */
		status = "disabled";              /* in zephyr\dts\arm\st\l4\stm32l4.dtsi:561 */
	};

	/* node '/vref' defined in zephyr\dts\arm\st\l4\stm32l4.dtsi:564 */
	vref: vref {
		compatible = "st,stm32-vref";      /* in zephyr\dts\arm\st\l4\stm32l4.dtsi:565 */
		vrefint-cal-addr = < 0x1fff75aa >; /* in zephyr\dts\arm\st\l4\stm32l4.dtsi:566 */
		vrefint-cal-mv = < 0xbb8 >;        /* in zephyr\dts\arm\st\l4\stm32l4.dtsi:567 */
		io-channels = < &adc1 0x0 >;       /* in zephyr\dts\arm\st\l4\stm32l4.dtsi:568 */
		status = "disabled";               /* in zephyr\dts\arm\st\l4\stm32l4.dtsi:569 */
	};

	/* node '/vbat' defined in zephyr\dts\arm\st\l4\stm32l4.dtsi:572 */
	vbat: vbat {
		compatible = "st,stm32-vbat"; /* in zephyr\dts\arm\st\l4\stm32l4.dtsi:573 */
		ratio = < 0x3 >;              /* in zephyr\dts\arm\st\l4\stm32l4.dtsi:574 */
		io-channels = < &adc1 0x12 >; /* in zephyr\dts\arm\st\l4\stm32l4.dtsi:575 */
		status = "disabled";          /* in zephyr\dts\arm\st\l4\stm32l4.dtsi:576 */
	};

	/* node '/smbus1' defined in zephyr\dts\arm\st\l4\stm32l4.dtsi:579 */
	smbus1: smbus1 {
		compatible = "st,stm32-smbus"; /* in zephyr\dts\arm\st\l4\stm32l4.dtsi:580 */
		#address-cells = < 0x1 >;      /* in zephyr\dts\arm\st\l4\stm32l4.dtsi:581 */
		#size-cells = < 0x0 >;         /* in zephyr\dts\arm\st\l4\stm32l4.dtsi:582 */
		i2c = < &i2c1 >;               /* in zephyr\dts\arm\st\l4\stm32l4.dtsi:583 */
		status = "disabled";           /* in zephyr\dts\arm\st\l4\stm32l4.dtsi:584 */
	};

	/* node '/smbus3' defined in zephyr\dts\arm\st\l4\stm32l4.dtsi:587 */
	smbus3: smbus3 {
		compatible = "st,stm32-smbus"; /* in zephyr\dts\arm\st\l4\stm32l4.dtsi:588 */
		#address-cells = < 0x1 >;      /* in zephyr\dts\arm\st\l4\stm32l4.dtsi:589 */
		#size-cells = < 0x0 >;         /* in zephyr\dts\arm\st\l4\stm32l4.dtsi:590 */
		i2c = < &i2c3 >;               /* in zephyr\dts\arm\st\l4\stm32l4.dtsi:591 */
		status = "disabled";           /* in zephyr\dts\arm\st\l4\stm32l4.dtsi:592 */
	};

	/* node '/memory@10000000' defined in zephyr\dts\arm\st\l4\stm32l4p5.dtsi:21 */
	sram1: memory@10000000 {
		compatible = "zephyr,memory-region",
		             "mmio-sram";            /* in zephyr\dts\arm\st\l4\stm32l4p5.dtsi:22 */
		zephyr,memory-region = "SRAM1";      /* in zephyr\dts\arm\st\l4\stm32l4p5.dtsi:23 */
		reg = < 0x10000000 0x10000 >;        /* in zephyr\dts\arm\st\l4\stm32l4r5.dtsi:19 */
	};

	/* node '/otgfs_phy' defined in zephyr\dts\arm\st\l4\stm32l4p5.dtsi:466 */
	otgfs_phy: otgfs_phy {
		compatible = "usb-nop-xceiv"; /* in zephyr\dts\arm\st\l4\stm32l4p5.dtsi:467 */
		#phy-cells = < 0x0 >;         /* in zephyr\dts\arm\st\l4\stm32l4p5.dtsi:468 */
		phandle = < 0x1b >;           /* in zephyr\dts\arm\st\l4\stm32l4p5.dtsi:364 */
	};

	/* node '/smbus2' defined in zephyr\dts\arm\st\l4\stm32l4p5.dtsi:471 */
	smbus2: smbus2 {
		compatible = "st,stm32-smbus"; /* in zephyr\dts\arm\st\l4\stm32l4p5.dtsi:472 */
		#address-cells = < 0x1 >;      /* in zephyr\dts\arm\st\l4\stm32l4p5.dtsi:473 */
		#size-cells = < 0x0 >;         /* in zephyr\dts\arm\st\l4\stm32l4p5.dtsi:474 */
		i2c = < &i2c2 >;               /* in zephyr\dts\arm\st\l4\stm32l4p5.dtsi:475 */
		status = "disabled";           /* in zephyr\dts\arm\st\l4\stm32l4p5.dtsi:476 */
	};

	/* node '/smbus4' defined in zephyr\dts\arm\st\l4\stm32l4p5.dtsi:479 */
	smbus4: smbus4 {
		compatible = "st,stm32-smbus"; /* in zephyr\dts\arm\st\l4\stm32l4p5.dtsi:480 */
		#address-cells = < 0x1 >;      /* in zephyr\dts\arm\st\l4\stm32l4p5.dtsi:481 */
		#size-cells = < 0x0 >;         /* in zephyr\dts\arm\st\l4\stm32l4p5.dtsi:482 */
		i2c = < &i2c4 >;               /* in zephyr\dts\arm\st\l4\stm32l4p5.dtsi:483 */
		status = "disabled";           /* in zephyr\dts\arm\st\l4\stm32l4p5.dtsi:484 */
	};

	/* node '/memory@20040000' defined in zephyr\dts\arm\st\l4\stm32l4r5.dtsi:22 */
	sram2: memory@20040000 {
		compatible = "zephyr,memory-region",
		             "mmio-sram";            /* in zephyr\dts\arm\st\l4\stm32l4r5.dtsi:23 */
		zephyr,memory-region = "SRAM2";      /* in zephyr\dts\arm\st\l4\stm32l4r5.dtsi:24 */
		reg = < 0x20040000 0x60000 >;        /* in zephyr\dts\arm\st\l4\stm32l4r5.dtsi:25 */
	};

	/* node '/connector' defined in zephyr\boards\st\b_l4s5i_iot01a\arduino_r3_connector.dtsi:10 */
	arduino_header: connector {
		compatible = "arduino-header-r3";          /* in zephyr\boards\st\b_l4s5i_iot01a\arduino_r3_connector.dtsi:11 */
		#gpio-cells = < 0x2 >;                     /* in zephyr\boards\st\b_l4s5i_iot01a\arduino_r3_connector.dtsi:12 */
		gpio-map-mask = < 0xffffffff 0xffffffc0 >; /* in zephyr\boards\st\b_l4s5i_iot01a\arduino_r3_connector.dtsi:13 */
		gpio-map-pass-thru = < 0x0 0x3f >;         /* in zephyr\boards\st\b_l4s5i_iot01a\arduino_r3_connector.dtsi:14 */
		gpio-map = < 0x0 0x0 &gpioc 0x5 0x0 >,
		           < 0x1 0x0 &gpioc 0x4 0x0 >,
		           < 0x2 0x0 &gpioc 0x3 0x0 >,
		           < 0x3 0x0 &gpioc 0x2 0x0 >,
		           < 0x4 0x0 &gpioc 0x1 0x0 >,
		           < 0x5 0x0 &gpioc 0x0 0x0 >,
		           < 0x6 0x0 &gpioa 0x1 0x0 >,
		           < 0x7 0x0 &gpioa 0x0 0x0 >,
		           < 0x8 0x0 &gpiod 0xe 0x0 >,
		           < 0x9 0x0 &gpiob 0x0 0x0 >,
		           < 0xa 0x0 &gpioa 0x3 0x0 >,
		           < 0xb 0x0 &gpiob 0x4 0x0 >,
		           < 0xc 0x0 &gpiob 0x1 0x0 >,
		           < 0xd 0x0 &gpioa 0x4 0x0 >,
		           < 0xe 0x0 &gpiob 0x2 0x0 >,
		           < 0xf 0x0 &gpioa 0xf 0x0 >,
		           < 0x10 0x0 &gpioa 0x2 0x0 >,
		           < 0x11 0x0 &gpioa 0x7 0x0 >,
		           < 0x12 0x0 &gpioa 0x6 0x0 >,
		           < 0x13 0x0 &gpioa 0x5 0x0 >,
		           < 0x14 0x0 &gpiob 0x9 0x0 >,
		           < 0x15 0x0 &gpiob 0x8 0x0 >;    /* in zephyr\boards\st\b_l4s5i_iot01a\arduino_r3_connector.dtsi:15 */
	};

	/* node '/leds' defined in zephyr\boards\st\b_l4s5i_iot01a\b_l4s5i_iot01a.dts:28 */
	leds {
		compatible = "gpio-leds"; /* in zephyr\boards\st\b_l4s5i_iot01a\b_l4s5i_iot01a.dts:29 */

		/* node '/leds/led_1' defined in zephyr\boards\st\b_l4s5i_iot01a\b_l4s5i_iot01a.dts:31 */
		green_led_1: led_1 {
			gpios = < &gpioa 0x5 0x0 >; /* in zephyr\boards\st\b_l4s5i_iot01a\b_l4s5i_iot01a.dts:32 */
			label = "User LD1";         /* in zephyr\boards\st\b_l4s5i_iot01a\b_l4s5i_iot01a.dts:33 */
		};

		/* node '/leds/led_2' defined in zephyr\boards\st\b_l4s5i_iot01a\b_l4s5i_iot01a.dts:36 */
		green_led_2: led_2 {
			gpios = < &gpiob 0xe 0x0 >; /* in zephyr\boards\st\b_l4s5i_iot01a\b_l4s5i_iot01a.dts:37 */
			label = "User LD2";         /* in zephyr\boards\st\b_l4s5i_iot01a\b_l4s5i_iot01a.dts:38 */
		};
	};

	/* node '/gpio_keys' defined in zephyr\boards\st\b_l4s5i_iot01a\b_l4s5i_iot01a.dts:42 */
	gpio_keys {
		compatible = "gpio-keys"; /* in zephyr\boards\st\b_l4s5i_iot01a\b_l4s5i_iot01a.dts:43 */

		/* node '/gpio_keys/button' defined in zephyr\boards\st\b_l4s5i_iot01a\b_l4s5i_iot01a.dts:45 */
		user_button: button {
			label = "User";             /* in zephyr\boards\st\b_l4s5i_iot01a\b_l4s5i_iot01a.dts:46 */
			gpios = < &gpioc 0xd 0x1 >; /* in zephyr\boards\st\b_l4s5i_iot01a\b_l4s5i_iot01a.dts:47 */
			zephyr,code = < 0xb >;      /* in zephyr\boards\st\b_l4s5i_iot01a\b_l4s5i_iot01a.dts:48 */
		};
	};
};
